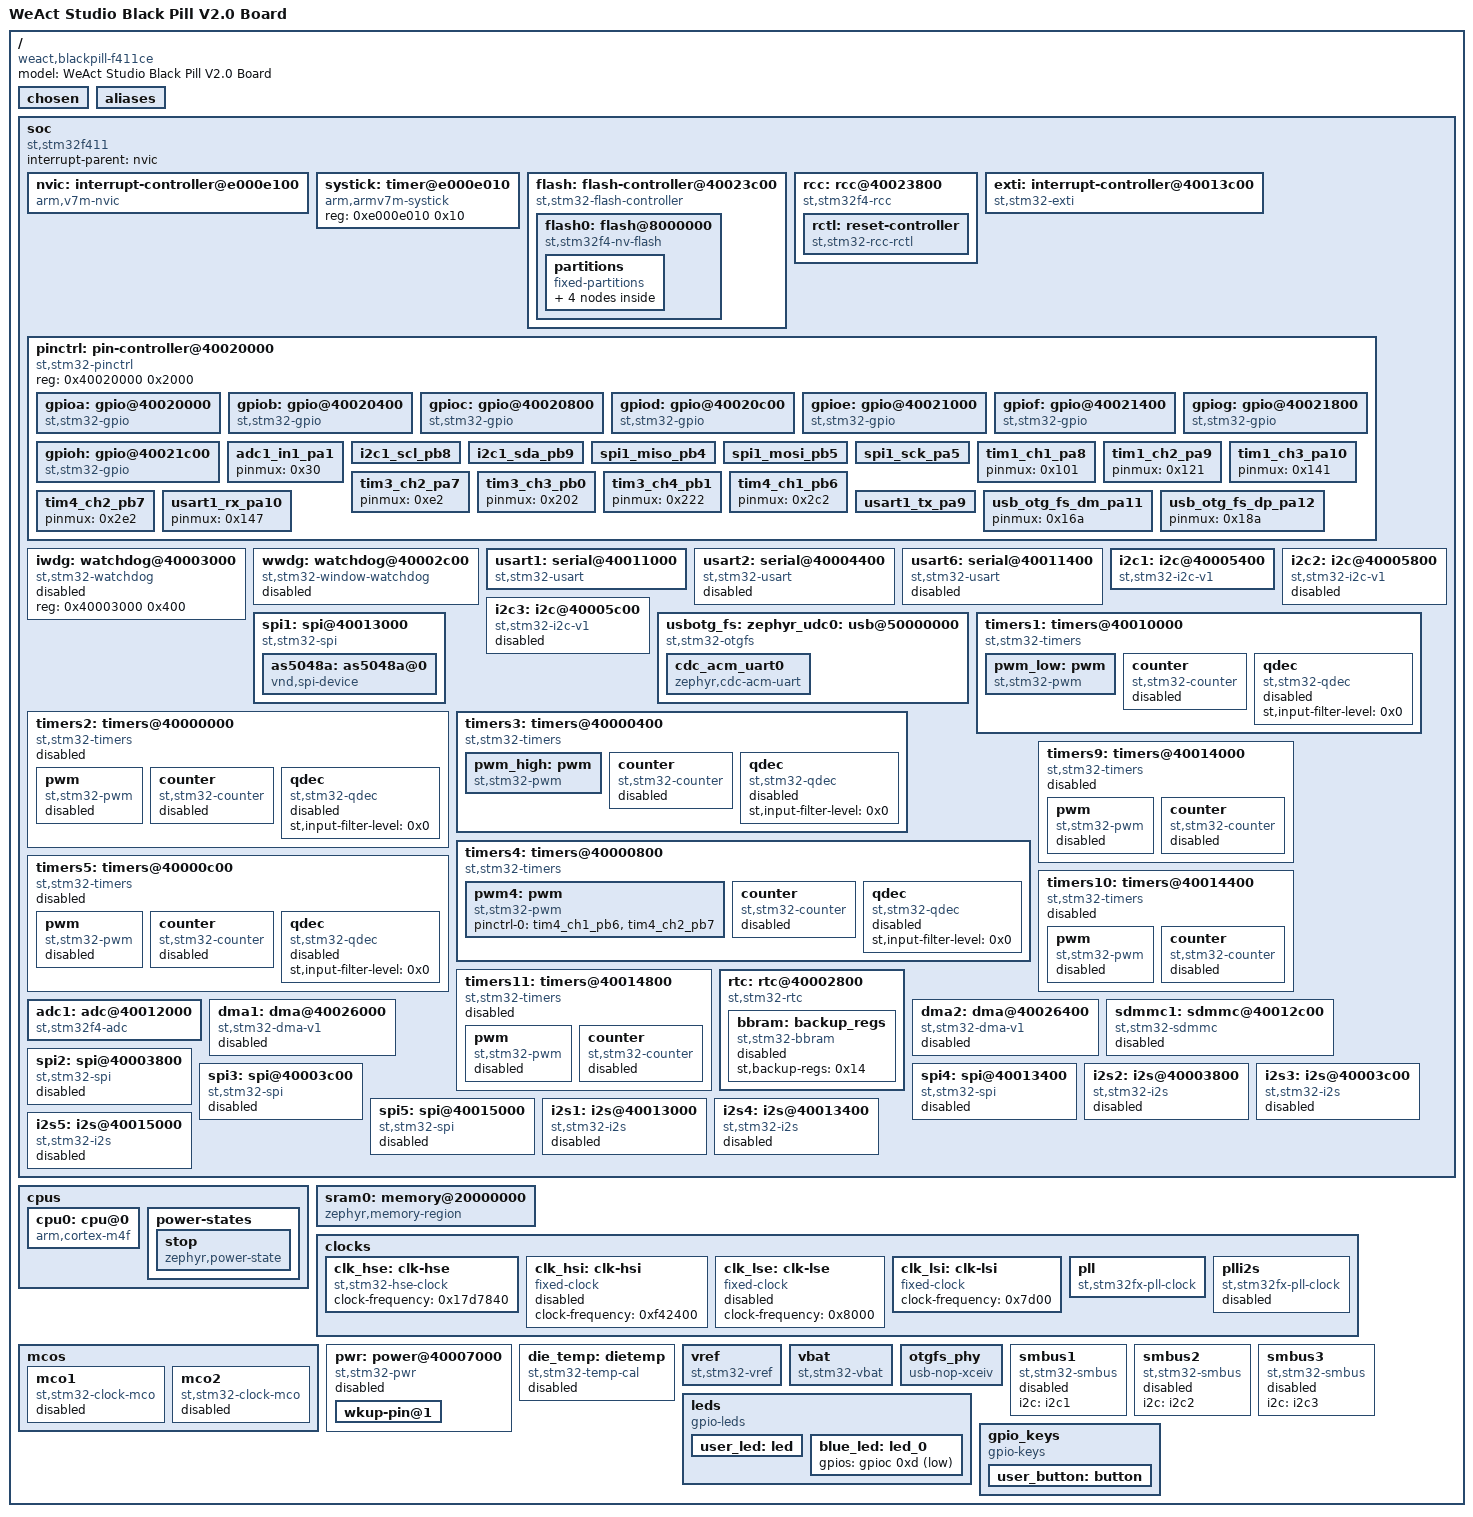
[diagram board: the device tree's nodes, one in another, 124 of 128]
/dts-v1/;

/* node '/' defined in zephyr/dts/common/skeleton.dtsi:9 */
/ {
	#address-cells = < 0x1 >;                     /* in zephyr/dts/common/skeleton.dtsi:10 */
	#size-cells = < 0x1 >;                        /* in zephyr/dts/common/skeleton.dtsi:11 */
	model = "WeAct Studio Black Pill V2.0 Board"; /* in zephyr/boards/weact/blackpill_f411ce/blackpill_f411ce.dts:14 */
	compatible = "weact,blackpill-f411ce";        /* in zephyr/boards/weact/blackpill_f411ce/blackpill_f411ce.dts:15 */

	/* node '/chosen' defined in zephyr/dts/common/skeleton.dtsi:13 */
	chosen {
		zephyr,flash-controller = &flash;  /* in zephyr/dts/arm/st/f4/stm32f4.dtsi:26 */
		zephyr,cortex-m-idle-timer = &rtc; /* in zephyr/dts/arm/st/f4/stm32f4.dtsi:27 */
		zephyr,shell-uart = &usart1;       /* in zephyr/boards/weact/blackpill_f411ce/blackpill_f411ce.dts:19 */
		zephyr,sram = &sram0;              /* in zephyr/boards/weact/blackpill_f411ce/blackpill_f411ce.dts:20 */
		zephyr,flash = &flash0;            /* in zephyr/boards/weact/blackpill_f411ce/blackpill_f411ce.dts:21 */
		zephyr,console = &cdc_acm_uart0;   /* in haptic/app.overlay:4 */
	};

	/* node '/aliases' defined in zephyr/dts/common/skeleton.dtsi:15 */
	aliases {
		volt-sensor0 = &vref; /* in zephyr/boards/weact/blackpill_f411ce/blackpill_f411ce.dts:46 */
		volt-sensor1 = &vbat; /* in zephyr/boards/weact/blackpill_f411ce/blackpill_f411ce.dts:47 */
		led0 = &blue_led;     /* in haptic/app.overlay:16 */
		sw0 = &user_button;   /* in haptic/app.overlay:17 */
	};

	/* node '/soc' defined in zephyr/dts/arm/armv7-m.dtsi:6 */
	soc {
		#address-cells = < 0x1 >;     /* in zephyr/dts/arm/armv7-m.dtsi:7 */
		#size-cells = < 0x1 >;        /* in zephyr/dts/arm/armv7-m.dtsi:8 */
		interrupt-parent = < &nvic >; /* in zephyr/dts/arm/armv7-m.dtsi:10 */
		ranges;                       /* in zephyr/dts/arm/armv7-m.dtsi:11 */
		compatible = "st,stm32f411",
		             "st,stm32f4",
		             "simple-bus";    /* in zephyr/dts/arm/st/f4/stm32f411.dtsi:11 */

		/* node '/soc/interrupt-controller@e000e100' defined in zephyr/dts/arm/armv7-m.dtsi:13 */
		nvic: interrupt-controller@e000e100 {
			#address-cells = < 0x1 >;            /* in zephyr/dts/arm/armv7-m.dtsi:14 */
			compatible = "arm,v7m-nvic";         /* in zephyr/dts/arm/armv7-m.dtsi:15 */
			reg = < 0xe000e100 0xc00 >;          /* in zephyr/dts/arm/armv7-m.dtsi:16 */
			interrupt-controller;                /* in zephyr/dts/arm/armv7-m.dtsi:17 */
			#interrupt-cells = < 0x2 >;          /* in zephyr/dts/arm/armv7-m.dtsi:18 */
			arm,num-irq-priority-bits = < 0x4 >; /* in zephyr/dts/arm/st/f4/stm32f4.dtsi:678 */
			phandle = < 0x1 >;                   /* in zephyr/dts/arm/armv7-m.dtsi:10 */
		};

		/* node '/soc/timer@e000e010' defined in zephyr/dts/arm/armv7-m.dtsi:21 */
		systick: timer@e000e010 {
			compatible = "arm,armv7m-systick"; /* in zephyr/dts/arm/armv7-m.dtsi:22 */
			reg = < 0xe000e010 0x10 >;         /* in zephyr/dts/arm/armv7-m.dtsi:23 */
		};

		/* node '/soc/flash-controller@40023c00' defined in zephyr/dts/arm/st/f4/stm32f4.dtsi:110 */
		flash: flash-controller@40023c00 {
			compatible = "st,stm32-flash-controller",
			             "st,stm32f4-flash-controller"; /* in zephyr/dts/arm/st/f4/stm32f4.dtsi:111 */
			reg = < 0x40023c00 0x400 >;                 /* in zephyr/dts/arm/st/f4/stm32f4.dtsi:112 */
			interrupts = < 0x4 0x0 >;                   /* in zephyr/dts/arm/st/f4/stm32f4.dtsi:113 */
			#address-cells = < 0x1 >;                   /* in zephyr/dts/arm/st/f4/stm32f4.dtsi:115 */
			#size-cells = < 0x1 >;                      /* in zephyr/dts/arm/st/f4/stm32f4.dtsi:116 */

			/* node '/soc/flash-controller@40023c00/flash@8000000' defined in zephyr/dts/arm/st/f4/stm32f4.dtsi:118 */
			flash0: flash@8000000 {
				compatible = "st,stm32f4-nv-flash",
				             "st,stm32-nv-flash",
				             "soc-nv-flash";        /* in zephyr/dts/arm/st/f4/stm32f4.dtsi:119 */
				write-block-size = < 0x1 >;         /* in zephyr/dts/arm/st/f4/stm32f4.dtsi:122 */
				max-erase-time = < 0xfa0 >;         /* in zephyr/dts/arm/st/f4/stm32f4.dtsi:124 */
				reg = < 0x8000000 0x80000 >;        /* in zephyr/dts/arm/st/f4/stm32f411Xe.dtsi:17 */

				/* node '/soc/flash-controller@40023c00/flash@8000000/partitions' defined in zephyr/boards/weact/blackpill_f411ce/blackpill_f411ce.dts:52 */
				partitions {
					compatible = "fixed-partitions"; /* in zephyr/boards/weact/blackpill_f411ce/blackpill_f411ce.dts:53 */
					#address-cells = < 0x1 >;        /* in zephyr/boards/weact/blackpill_f411ce/blackpill_f411ce.dts:54 */
					#size-cells = < 0x1 >;           /* in zephyr/boards/weact/blackpill_f411ce/blackpill_f411ce.dts:55 */

					/* node '/soc/flash-controller@40023c00/flash@8000000/partitions/partition@0' defined in zephyr/boards/weact/blackpill_f411ce/blackpill_f411ce.dts:57 */
					boot_partition: partition@0 {
						label = "mcuboot";    /* in zephyr/boards/weact/blackpill_f411ce/blackpill_f411ce.dts:58 */
						reg = < 0x0 0x8000 >; /* in zephyr/boards/weact/blackpill_f411ce/blackpill_f411ce.dts:59 */
						read-only;            /* in zephyr/boards/weact/blackpill_f411ce/blackpill_f411ce.dts:60 */
					};

					/* node '/soc/flash-controller@40023c00/flash@8000000/partitions/partition@20000' defined in zephyr/boards/weact/blackpill_f411ce/blackpill_f411ce.dts:69 */
					slot0_partition: partition@20000 {
						label = "image-0";         /* in zephyr/boards/weact/blackpill_f411ce/blackpill_f411ce.dts:70 */
						reg = < 0x20000 0x20000 >; /* in zephyr/boards/weact/blackpill_f411ce/blackpill_f411ce.dts:71 */
					};

					/* node '/soc/flash-controller@40023c00/flash@8000000/partitions/partition@40000' defined in zephyr/boards/weact/blackpill_f411ce/blackpill_f411ce.dts:74 */
					slot1_partition: partition@40000 {
						label = "image-1";         /* in zephyr/boards/weact/blackpill_f411ce/blackpill_f411ce.dts:75 */
						reg = < 0x40000 0x20000 >; /* in zephyr/boards/weact/blackpill_f411ce/blackpill_f411ce.dts:76 */
					};

					/* node '/soc/flash-controller@40023c00/flash@8000000/partitions/partition@60000' defined in zephyr/boards/weact/blackpill_f411ce/blackpill_f411ce.dts:79 */
					scratch_partition: partition@60000 {
						label = "image-scratch";   /* in zephyr/boards/weact/blackpill_f411ce/blackpill_f411ce.dts:80 */
						reg = < 0x60000 0x20000 >; /* in zephyr/boards/weact/blackpill_f411ce/blackpill_f411ce.dts:81 */
					};
				};
			};
		};

		/* node '/soc/rcc@40023800' defined in zephyr/dts/arm/st/f4/stm32f4.dtsi:128 */
		rcc: rcc@40023800 {
			compatible = "st,stm32f4-rcc";   /* in zephyr/dts/arm/st/f4/stm32f4.dtsi:129 */
			#clock-cells = < 0x2 >;          /* in zephyr/dts/arm/st/f4/stm32f4.dtsi:130 */
			reg = < 0x40023800 0x400 >;      /* in zephyr/dts/arm/st/f4/stm32f4.dtsi:131 */
			clocks = < &pll >;               /* in zephyr/boards/weact/blackpill_f411ce/blackpill_f411ce.dts:156 */
			clock-frequency = < 0x5b8d800 >; /* in zephyr/boards/weact/blackpill_f411ce/blackpill_f411ce.dts:157 */
			ahb-prescaler = < 0x1 >;         /* in zephyr/boards/weact/blackpill_f411ce/blackpill_f411ce.dts:158 */
			apb1-prescaler = < 0x2 >;        /* in zephyr/boards/weact/blackpill_f411ce/blackpill_f411ce.dts:159 */
			apb2-prescaler = < 0x1 >;        /* in zephyr/boards/weact/blackpill_f411ce/blackpill_f411ce.dts:160 */
			phandle = < 0x3 >;               /* in zephyr/dts/arm/st/f4/stm32f4.dtsi:145 */

			/* node '/soc/rcc@40023800/reset-controller' defined in zephyr/dts/arm/st/f4/stm32f4.dtsi:133 */
			rctl: reset-controller {
				compatible = "st,stm32-rcc-rctl"; /* in zephyr/dts/arm/st/f4/stm32f4.dtsi:134 */
				#reset-cells = < 0x1 >;           /* in zephyr/dts/arm/st/f4/stm32f4.dtsi:135 */
				phandle = < 0x4 >;                /* in zephyr/dts/arm/st/f4/stm32f4.dtsi:244 */
			};
		};

		/* node '/soc/interrupt-controller@40013c00' defined in zephyr/dts/arm/st/f4/stm32f4.dtsi:139 */
		exti: interrupt-controller@40013c00 {
			compatible = "st,stm32-exti";  /* in zephyr/dts/arm/st/f4/stm32f4.dtsi:140 */
			interrupt-controller;          /* in zephyr/dts/arm/st/f4/stm32f4.dtsi:141 */
			#interrupt-cells = < 0x1 >;    /* in zephyr/dts/arm/st/f4/stm32f4.dtsi:142 */
			#address-cells = < 0x0 >;      /* in zephyr/dts/arm/st/f4/stm32f4.dtsi:143 */
			reg = < 0x40013c00 0x400 >;    /* in zephyr/dts/arm/st/f4/stm32f4.dtsi:144 */
			clocks = < &rcc 0x44 0x4000 >; /* in zephyr/dts/arm/st/f4/stm32f4.dtsi:145 */
			num-lines = < 0x20 >;          /* in zephyr/dts/arm/st/f4/stm32f4.dtsi:146 */
			interrupts = < 0x6 0x0 >,
			             < 0x7 0x0 >,
			             < 0x8 0x0 >,
			             < 0x9 0x0 >,
			             < 0xa 0x0 >,
			             < 0x17 0x0 >,
			             < 0x28 0x0 >;     /* in zephyr/dts/arm/st/f4/stm32f4.dtsi:147 */
			interrupt-names = "line0",
			                  "line1",
			                  "line2",
			                  "line3",
			                  "line4",
			                  "line5-9",
			                  "line10-15"; /* in zephyr/dts/arm/st/f4/stm32f4.dtsi:149 */
			line-ranges = < 0x0 0x1 >,
			              < 0x1 0x1 >,
			              < 0x2 0x1 >,
			              < 0x3 0x1 >,
			              < 0x4 0x1 >,
			              < 0x5 0x5 >,
			              < 0xa 0x6 >;     /* in zephyr/dts/arm/st/f4/stm32f4.dtsi:151 */
		};

		/* node '/soc/pin-controller@40020000' defined in zephyr/dts/arm/st/f4/stm32f4.dtsi:155 */
		pinctrl: pin-controller@40020000 {
			compatible = "st,stm32-pinctrl"; /* in zephyr/dts/arm/st/f4/stm32f4.dtsi:156 */
			#address-cells = < 0x1 >;        /* in zephyr/dts/arm/st/f4/stm32f4.dtsi:157 */
			#size-cells = < 0x1 >;           /* in zephyr/dts/arm/st/f4/stm32f4.dtsi:158 */
			reg = < 0x40020000 0x2000 >;     /* in zephyr/dts/arm/st/f4/stm32f4.dtsi:159 */

			/* node '/soc/pin-controller@40020000/gpio@40020000' defined in zephyr/dts/arm/st/f4/stm32f4.dtsi:161 */
			gpioa: gpio@40020000 {
				compatible = "st,stm32-gpio"; /* in zephyr/dts/arm/st/f4/stm32f4.dtsi:162 */
				gpio-controller;              /* in zephyr/dts/arm/st/f4/stm32f4.dtsi:163 */
				#gpio-cells = < 0x2 >;        /* in zephyr/dts/arm/st/f4/stm32f4.dtsi:164 */
				reg = < 0x40020000 0x400 >;   /* in zephyr/dts/arm/st/f4/stm32f4.dtsi:165 */
				clocks = < &rcc 0x30 0x1 >;   /* in zephyr/dts/arm/st/f4/stm32f4.dtsi:166 */
				phandle = < 0xc >;            /* in haptic/app.overlay:34 */
			};

			/* node '/soc/pin-controller@40020000/gpio@40020400' defined in zephyr/dts/arm/st/f4/stm32f4.dtsi:169 */
			gpiob: gpio@40020400 {
				compatible = "st,stm32-gpio"; /* in zephyr/dts/arm/st/f4/stm32f4.dtsi:170 */
				gpio-controller;              /* in zephyr/dts/arm/st/f4/stm32f4.dtsi:171 */
				#gpio-cells = < 0x2 >;        /* in zephyr/dts/arm/st/f4/stm32f4.dtsi:172 */
				reg = < 0x40020400 0x400 >;   /* in zephyr/dts/arm/st/f4/stm32f4.dtsi:173 */
				clocks = < &rcc 0x30 0x2 >;   /* in zephyr/dts/arm/st/f4/stm32f4.dtsi:174 */
			};

			/* node '/soc/pin-controller@40020000/gpio@40020800' defined in zephyr/dts/arm/st/f4/stm32f4.dtsi:177 */
			gpioc: gpio@40020800 {
				compatible = "st,stm32-gpio"; /* in zephyr/dts/arm/st/f4/stm32f4.dtsi:178 */
				gpio-controller;              /* in zephyr/dts/arm/st/f4/stm32f4.dtsi:179 */
				#gpio-cells = < 0x2 >;        /* in zephyr/dts/arm/st/f4/stm32f4.dtsi:180 */
				reg = < 0x40020800 0x400 >;   /* in zephyr/dts/arm/st/f4/stm32f4.dtsi:181 */
				clocks = < &rcc 0x30 0x4 >;   /* in zephyr/dts/arm/st/f4/stm32f4.dtsi:182 */
				phandle = < 0x21 >;           /* in zephyr/boards/weact/blackpill_f411ce/blackpill_f411ce.dts:28 */
			};

			/* node '/soc/pin-controller@40020000/gpio@40020c00' defined in zephyr/dts/arm/st/f4/stm32f4.dtsi:185 */
			gpiod: gpio@40020c00 {
				compatible = "st,stm32-gpio"; /* in zephyr/dts/arm/st/f4/stm32f4.dtsi:186 */
				gpio-controller;              /* in zephyr/dts/arm/st/f4/stm32f4.dtsi:187 */
				#gpio-cells = < 0x2 >;        /* in zephyr/dts/arm/st/f4/stm32f4.dtsi:188 */
				reg = < 0x40020c00 0x400 >;   /* in zephyr/dts/arm/st/f4/stm32f4.dtsi:189 */
				clocks = < &rcc 0x30 0x8 >;   /* in zephyr/dts/arm/st/f4/stm32f4.dtsi:190 */
			};

			/* node '/soc/pin-controller@40020000/gpio@40021000' defined in zephyr/dts/arm/st/f4/stm32f4.dtsi:193 */
			gpioe: gpio@40021000 {
				compatible = "st,stm32-gpio"; /* in zephyr/dts/arm/st/f4/stm32f4.dtsi:194 */
				gpio-controller;              /* in zephyr/dts/arm/st/f4/stm32f4.dtsi:195 */
				#gpio-cells = < 0x2 >;        /* in zephyr/dts/arm/st/f4/stm32f4.dtsi:196 */
				reg = < 0x40021000 0x400 >;   /* in zephyr/dts/arm/st/f4/stm32f4.dtsi:197 */
				clocks = < &rcc 0x30 0x10 >;  /* in zephyr/dts/arm/st/f4/stm32f4.dtsi:198 */
			};

			/* node '/soc/pin-controller@40020000/gpio@40021400' defined in zephyr/dts/arm/st/f4/stm32f4.dtsi:201 */
			gpiof: gpio@40021400 {
				compatible = "st,stm32-gpio"; /* in zephyr/dts/arm/st/f4/stm32f4.dtsi:202 */
				gpio-controller;              /* in zephyr/dts/arm/st/f4/stm32f4.dtsi:203 */
				#gpio-cells = < 0x2 >;        /* in zephyr/dts/arm/st/f4/stm32f4.dtsi:204 */
				reg = < 0x40021400 0x400 >;   /* in zephyr/dts/arm/st/f4/stm32f4.dtsi:205 */
				clocks = < &rcc 0x30 0x20 >;  /* in zephyr/dts/arm/st/f4/stm32f4.dtsi:206 */
			};

			/* node '/soc/pin-controller@40020000/gpio@40021800' defined in zephyr/dts/arm/st/f4/stm32f4.dtsi:209 */
			gpiog: gpio@40021800 {
				compatible = "st,stm32-gpio"; /* in zephyr/dts/arm/st/f4/stm32f4.dtsi:210 */
				gpio-controller;              /* in zephyr/dts/arm/st/f4/stm32f4.dtsi:211 */
				#gpio-cells = < 0x2 >;        /* in zephyr/dts/arm/st/f4/stm32f4.dtsi:212 */
				reg = < 0x40021800 0x400 >;   /* in zephyr/dts/arm/st/f4/stm32f4.dtsi:213 */
				clocks = < &rcc 0x30 0x40 >;  /* in zephyr/dts/arm/st/f4/stm32f4.dtsi:214 */
			};

			/* node '/soc/pin-controller@40020000/gpio@40021c00' defined in zephyr/dts/arm/st/f4/stm32f4.dtsi:217 */
			gpioh: gpio@40021c00 {
				compatible = "st,stm32-gpio"; /* in zephyr/dts/arm/st/f4/stm32f4.dtsi:218 */
				gpio-controller;              /* in zephyr/dts/arm/st/f4/stm32f4.dtsi:219 */
				#gpio-cells = < 0x2 >;        /* in zephyr/dts/arm/st/f4/stm32f4.dtsi:220 */
				reg = < 0x40021c00 0x400 >;   /* in zephyr/dts/arm/st/f4/stm32f4.dtsi:221 */
				clocks = < &rcc 0x30 0x80 >;  /* in zephyr/dts/arm/st/f4/stm32f4.dtsi:222 */
			};

			/* node '/soc/pin-controller@40020000/adc1_in1_pa1' defined in modules/hal/stm32/dts/st/f4/stm32f411c(c-e)ux-pinctrl.dtsi:19 */
			adc1_in1_pa1: adc1_in1_pa1 {
				pinmux = < 0x30 >;  /* in modules/hal/stm32/dts/st/f4/stm32f411c(c-e)ux-pinctrl.dtsi:20 */
				phandle = < 0x18 >; /* in zephyr/boards/weact/blackpill_f411ce/blackpill_f411ce.dts:130 */
			};

			/* node '/soc/pin-controller@40020000/i2c1_scl_pb8' defined in modules/hal/stm32/dts/st/f4/stm32f411c(c-e)ux-pinctrl.dtsi:209 */
			i2c1_scl_pb8: i2c1_scl_pb8 {
				pinmux = < 0x304 >; /* in modules/hal/stm32/dts/st/f4/stm32f411c(c-e)ux-pinctrl.dtsi:210 */
				bias-pull-up;       /* in modules/hal/stm32/dts/st/f4/stm32f411c(c-e)ux-pinctrl.dtsi:211 */
				drive-open-drain;   /* in modules/hal/stm32/dts/st/f4/stm32f411c(c-e)ux-pinctrl.dtsi:212 */
				phandle = < 0x7 >;  /* in zephyr/boards/weact/blackpill_f411ce/blackpill_f411ce.dts:104 */
			};

			/* node '/soc/pin-controller@40020000/i2c1_sda_pb9' defined in modules/hal/stm32/dts/st/f4/stm32f411c(c-e)ux-pinctrl.dtsi:235 */
			i2c1_sda_pb9: i2c1_sda_pb9 {
				pinmux = < 0x324 >; /* in modules/hal/stm32/dts/st/f4/stm32f411c(c-e)ux-pinctrl.dtsi:236 */
				bias-pull-up;       /* in modules/hal/stm32/dts/st/f4/stm32f411c(c-e)ux-pinctrl.dtsi:237 */
				drive-open-drain;   /* in modules/hal/stm32/dts/st/f4/stm32f411c(c-e)ux-pinctrl.dtsi:238 */
				phandle = < 0x8 >;  /* in zephyr/boards/weact/blackpill_f411ce/blackpill_f411ce.dts:104 */
			};

			/* node '/soc/pin-controller@40020000/spi1_miso_pb4' defined in modules/hal/stm32/dts/st/f4/stm32f411c(c-e)ux-pinctrl.dtsi:510 */
			spi1_miso_pb4: spi1_miso_pb4 {
				pinmux = < 0x285 >;            /* in modules/hal/stm32/dts/st/f4/stm32f411c(c-e)ux-pinctrl.dtsi:511 */
				bias-pull-down;                /* in modules/hal/stm32/dts/st/f4/stm32f411c(c-e)ux-pinctrl.dtsi:512 */
				slew-rate = "very-high-speed"; /* in modules/hal/stm32/dts/st/f4/stm32f411c(c-e)ux-pinctrl.dtsi:513 */
				phandle = < 0xa >;             /* in haptic/app.overlay:32 */
			};

			/* node '/soc/pin-controller@40020000/spi1_mosi_pb5' defined in modules/hal/stm32/dts/st/f4/stm32f411c(c-e)ux-pinctrl.dtsi:548 */
			spi1_mosi_pb5: spi1_mosi_pb5 {
				pinmux = < 0x2a5 >;            /* in modules/hal/stm32/dts/st/f4/stm32f411c(c-e)ux-pinctrl.dtsi:549 */
				bias-pull-down;                /* in modules/hal/stm32/dts/st/f4/stm32f411c(c-e)ux-pinctrl.dtsi:550 */
				slew-rate = "very-high-speed"; /* in modules/hal/stm32/dts/st/f4/stm32f411c(c-e)ux-pinctrl.dtsi:551 */
				phandle = < 0xb >;             /* in haptic/app.overlay:32 */
			};

			/* node '/soc/pin-controller@40020000/spi1_sck_pa5' defined in modules/hal/stm32/dts/st/f4/stm32f411c(c-e)ux-pinctrl.dtsi:636 */
			spi1_sck_pa5: spi1_sck_pa5 {
				pinmux = < 0xa5 >;             /* in modules/hal/stm32/dts/st/f4/stm32f411c(c-e)ux-pinctrl.dtsi:637 */
				bias-pull-down;                /* in modules/hal/stm32/dts/st/f4/stm32f411c(c-e)ux-pinctrl.dtsi:638 */
				slew-rate = "very-high-speed"; /* in modules/hal/stm32/dts/st/f4/stm32f411c(c-e)ux-pinctrl.dtsi:639 */
				phandle = < 0x9 >;             /* in haptic/app.overlay:32 */
			};

			/* node '/soc/pin-controller@40020000/tim1_ch1_pa8' defined in modules/hal/stm32/dts/st/f4/stm32f411c(c-e)ux-pinctrl.dtsi:704 */
			tim1_ch1_pa8: tim1_ch1_pa8 {
				pinmux = < 0x101 >; /* in modules/hal/stm32/dts/st/f4/stm32f411c(c-e)ux-pinctrl.dtsi:705 */
				phandle = < 0x10 >; /* in haptic/app.overlay:52 */
			};

			/* node '/soc/pin-controller@40020000/tim1_ch2_pa9' defined in modules/hal/stm32/dts/st/f4/stm32f411c(c-e)ux-pinctrl.dtsi:708 */
			tim1_ch2_pa9: tim1_ch2_pa9 {
				pinmux = < 0x121 >; /* in modules/hal/stm32/dts/st/f4/stm32f411c(c-e)ux-pinctrl.dtsi:709 */
				phandle = < 0x11 >; /* in haptic/app.overlay:52 */
			};

			/* node '/soc/pin-controller@40020000/tim1_ch3_pa10' defined in modules/hal/stm32/dts/st/f4/stm32f411c(c-e)ux-pinctrl.dtsi:712 */
			tim1_ch3_pa10: tim1_ch3_pa10 {
				pinmux = < 0x141 >; /* in modules/hal/stm32/dts/st/f4/stm32f411c(c-e)ux-pinctrl.dtsi:713 */
				phandle = < 0x12 >; /* in haptic/app.overlay:52 */
			};

			/* node '/soc/pin-controller@40020000/tim3_ch2_pa7' defined in modules/hal/stm32/dts/st/f4/stm32f411c(c-e)ux-pinctrl.dtsi:780 */
			tim3_ch2_pa7: tim3_ch2_pa7 {
				pinmux = < 0xe2 >;  /* in modules/hal/stm32/dts/st/f4/stm32f411c(c-e)ux-pinctrl.dtsi:781 */
				phandle = < 0x13 >; /* in haptic/app.overlay:62 */
			};

			/* node '/soc/pin-controller@40020000/tim3_ch3_pb0' defined in modules/hal/stm32/dts/st/f4/stm32f411c(c-e)ux-pinctrl.dtsi:784 */
			tim3_ch3_pb0: tim3_ch3_pb0 {
				pinmux = < 0x202 >; /* in modules/hal/stm32/dts/st/f4/stm32f411c(c-e)ux-pinctrl.dtsi:785 */
				phandle = < 0x14 >; /* in haptic/app.overlay:62 */
			};

			/* node '/soc/pin-controller@40020000/tim3_ch4_pb1' defined in modules/hal/stm32/dts/st/f4/stm32f411c(c-e)ux-pinctrl.dtsi:788 */
			tim3_ch4_pb1: tim3_ch4_pb1 {
				pinmux = < 0x222 >; /* in modules/hal/stm32/dts/st/f4/stm32f411c(c-e)ux-pinctrl.dtsi:789 */
				phandle = < 0x15 >; /* in haptic/app.overlay:62 */
			};

			/* node '/soc/pin-controller@40020000/tim4_ch1_pb6' defined in modules/hal/stm32/dts/st/f4/stm32f411c(c-e)ux-pinctrl.dtsi:800 */
			tim4_ch1_pb6: tim4_ch1_pb6 {
				pinmux = < 0x2c2 >; /* in modules/hal/stm32/dts/st/f4/stm32f411c(c-e)ux-pinctrl.dtsi:801 */
				phandle = < 0x16 >; /* in zephyr/boards/weact/blackpill_f411ce/blackpill_f411ce.dts:91 */
			};

			/* node '/soc/pin-controller@40020000/tim4_ch2_pb7' defined in modules/hal/stm32/dts/st/f4/stm32f411c(c-e)ux-pinctrl.dtsi:804 */
			tim4_ch2_pb7: tim4_ch2_pb7 {
				pinmux = < 0x2e2 >; /* in modules/hal/stm32/dts/st/f4/stm32f411c(c-e)ux-pinctrl.dtsi:805 */
				phandle = < 0x17 >; /* in zephyr/boards/weact/blackpill_f411ce/blackpill_f411ce.dts:91 */
			};

			/* node '/soc/pin-controller@40020000/usart1_rx_pa10' defined in modules/hal/stm32/dts/st/f4/stm32f411c(c-e)ux-pinctrl.dtsi:866 */
			usart1_rx_pa10: usart1_rx_pa10 {
				pinmux = < 0x147 >; /* in modules/hal/stm32/dts/st/f4/stm32f411c(c-e)ux-pinctrl.dtsi:867 */
				phandle = < 0x6 >;  /* in zephyr/boards/weact/blackpill_f411ce/blackpill_f411ce.dts:97 */
			};

			/* node '/soc/pin-controller@40020000/usart1_tx_pa9' defined in modules/hal/stm32/dts/st/f4/stm32f411c(c-e)ux-pinctrl.dtsi:888 */
			usart1_tx_pa9: usart1_tx_pa9 {
				pinmux = < 0x127 >; /* in modules/hal/stm32/dts/st/f4/stm32f411c(c-e)ux-pinctrl.dtsi:889 */
				bias-pull-up;       /* in modules/hal/stm32/dts/st/f4/stm32f411c(c-e)ux-pinctrl.dtsi:890 */
				phandle = < 0x5 >;  /* in zephyr/boards/weact/blackpill_f411ce/blackpill_f411ce.dts:97 */
			};

			/* node '/soc/pin-controller@40020000/usb_otg_fs_dm_pa11' defined in modules/hal/stm32/dts/st/f4/stm32f411c(c-e)ux-pinctrl.dtsi:927 */
			usb_otg_fs_dm_pa11: usb_otg_fs_dm_pa11 {
				pinmux = < 0x16a >; /* in modules/hal/stm32/dts/st/f4/stm32f411c(c-e)ux-pinctrl.dtsi:928 */
				phandle = < 0xe >;  /* in zephyr/boards/weact/blackpill_f411ce/blackpill_f411ce.dts:124 */
			};

			/* node '/soc/pin-controller@40020000/usb_otg_fs_dp_pa12' defined in modules/hal/stm32/dts/st/f4/stm32f411c(c-e)ux-pinctrl.dtsi:931 */
			usb_otg_fs_dp_pa12: usb_otg_fs_dp_pa12 {
				pinmux = < 0x18a >; /* in modules/hal/stm32/dts/st/f4/stm32f411c(c-e)ux-pinctrl.dtsi:932 */
				phandle = < 0xf >;  /* in zephyr/boards/weact/blackpill_f411ce/blackpill_f411ce.dts:124 */
			};
		};

		/* node '/soc/watchdog@40003000' defined in zephyr/dts/arm/st/f4/stm32f4.dtsi:226 */
		iwdg: watchdog@40003000 {
			compatible = "st,stm32-watchdog"; /* in zephyr/dts/arm/st/f4/stm32f4.dtsi:227 */
			reg = < 0x40003000 0x400 >;       /* in zephyr/dts/arm/st/f4/stm32f4.dtsi:228 */
			status = "disabled";              /* in zephyr/dts/arm/st/f4/stm32f4.dtsi:229 */
		};

		/* node '/soc/watchdog@40002c00' defined in zephyr/dts/arm/st/f4/stm32f4.dtsi:232 */
		wwdg: watchdog@40002c00 {
			compatible = "st,stm32-window-watchdog"; /* in zephyr/dts/arm/st/f4/stm32f4.dtsi:233 */
			reg = < 0x40002c00 0x400 >;              /* in zephyr/dts/arm/st/f4/stm32f4.dtsi:234 */
			clocks = < &rcc 0x40 0x800 >;            /* in zephyr/dts/arm/st/f4/stm32f4.dtsi:235 */
			interrupts = < 0x0 0x7 >;                /* in zephyr/dts/arm/st/f4/stm32f4.dtsi:236 */
			status = "disabled";                     /* in zephyr/dts/arm/st/f4/stm32f4.dtsi:237 */
		};

		/* node '/soc/serial@40011000' defined in zephyr/dts/arm/st/f4/stm32f4.dtsi:240 */
		usart1: serial@40011000 {
			compatible = "st,stm32-usart",
			             "st,stm32-uart";                   /* in zephyr/dts/arm/st/f4/stm32f4.dtsi:241 */
			reg = < 0x40011000 0x400 >;                     /* in zephyr/dts/arm/st/f4/stm32f4.dtsi:242 */
			clocks = < &rcc 0x44 0x10 >;                    /* in zephyr/dts/arm/st/f4/stm32f4.dtsi:243 */
			resets = < &rctl 0x484 >;                       /* in zephyr/dts/arm/st/f4/stm32f4.dtsi:244 */
			interrupts = < 0x25 0x0 >;                      /* in zephyr/dts/arm/st/f4/stm32f4.dtsi:245 */
			pinctrl-0 = < &usart1_tx_pa9 &usart1_rx_pa10 >; /* in zephyr/boards/weact/blackpill_f411ce/blackpill_f411ce.dts:97 */
			pinctrl-names = "default";                      /* in zephyr/boards/weact/blackpill_f411ce/blackpill_f411ce.dts:98 */
			status = "okay";                                /* in zephyr/boards/weact/blackpill_f411ce/blackpill_f411ce.dts:99 */
			current-speed = < 0x1c200 >;                    /* in zephyr/boards/weact/blackpill_f411ce/blackpill_f411ce.dts:100 */
		};

		/* node '/soc/serial@40004400' defined in zephyr/dts/arm/st/f4/stm32f4.dtsi:249 */
		usart2: serial@40004400 {
			compatible = "st,stm32-usart",
			             "st,stm32-uart";   /* in zephyr/dts/arm/st/f4/stm32f4.dtsi:250 */
			reg = < 0x40004400 0x400 >;     /* in zephyr/dts/arm/st/f4/stm32f4.dtsi:251 */
			clocks = < &rcc 0x40 0x20000 >; /* in zephyr/dts/arm/st/f4/stm32f4.dtsi:252 */
			resets = < &rctl 0x411 >;       /* in zephyr/dts/arm/st/f4/stm32f4.dtsi:253 */
			interrupts = < 0x26 0x0 >;      /* in zephyr/dts/arm/st/f4/stm32f4.dtsi:254 */
			status = "disabled";            /* in zephyr/dts/arm/st/f4/stm32f4.dtsi:255 */
		};

		/* node '/soc/serial@40011400' defined in zephyr/dts/arm/st/f4/stm32f4.dtsi:258 */
		usart6: serial@40011400 {
			compatible = "st,stm32-usart",
			             "st,stm32-uart";  /* in zephyr/dts/arm/st/f4/stm32f4.dtsi:259 */
			reg = < 0x40011400 0x400 >;    /* in zephyr/dts/arm/st/f4/stm32f4.dtsi:260 */
			clocks = < &rcc 0x44 0x20 >;   /* in zephyr/dts/arm/st/f4/stm32f4.dtsi:261 */
			resets = < &rctl 0x485 >;      /* in zephyr/dts/arm/st/f4/stm32f4.dtsi:262 */
			interrupts = < 0x47 0x0 >;     /* in zephyr/dts/arm/st/f4/stm32f4.dtsi:263 */
			status = "disabled";           /* in zephyr/dts/arm/st/f4/stm32f4.dtsi:264 */
		};

		/* node '/soc/i2c@40005400' defined in zephyr/dts/arm/st/f4/stm32f4.dtsi:267 */
		i2c1: i2c@40005400 {
			compatible = "st,stm32-i2c-v1";              /* in zephyr/dts/arm/st/f4/stm32f4.dtsi:268 */
			#address-cells = < 0x1 >;                    /* in zephyr/dts/arm/st/f4/stm32f4.dtsi:270 */
			#size-cells = < 0x0 >;                       /* in zephyr/dts/arm/st/f4/stm32f4.dtsi:271 */
			reg = < 0x40005400 0x400 >;                  /* in zephyr/dts/arm/st/f4/stm32f4.dtsi:272 */
			clocks = < &rcc 0x40 0x200000 >;             /* in zephyr/dts/arm/st/f4/stm32f4.dtsi:273 */
			interrupts = < 0x1f 0x0 >,
			             < 0x20 0x0 >;                   /* in zephyr/dts/arm/st/f4/stm32f4.dtsi:274 */
			interrupt-names = "event",
			                  "error";                   /* in zephyr/dts/arm/st/f4/stm32f4.dtsi:275 */
			pinctrl-0 = < &i2c1_scl_pb8 &i2c1_sda_pb9 >; /* in zephyr/boards/weact/blackpill_f411ce/blackpill_f411ce.dts:104 */
			pinctrl-names = "default";                   /* in zephyr/boards/weact/blackpill_f411ce/blackpill_f411ce.dts:105 */
			status = "okay";                             /* in zephyr/boards/weact/blackpill_f411ce/blackpill_f411ce.dts:106 */
			clock-frequency = < 0x61a80 >;               /* in zephyr/boards/weact/blackpill_f411ce/blackpill_f411ce.dts:107 */
			phandle = < 0x1e >;                          /* in zephyr/dts/arm/st/f4/stm32f4.dtsi:656 */
		};

		/* node '/soc/i2c@40005800' defined in zephyr/dts/arm/st/f4/stm32f4.dtsi:279 */
		i2c2: i2c@40005800 {
			compatible = "st,stm32-i2c-v1";  /* in zephyr/dts/arm/st/f4/stm32f4.dtsi:280 */
			clock-frequency = < 0x186a0 >;   /* in zephyr/dts/arm/st/f4/stm32f4.dtsi:281 */
			#address-cells = < 0x1 >;        /* in zephyr/dts/arm/st/f4/stm32f4.dtsi:282 */
			#size-cells = < 0x0 >;           /* in zephyr/dts/arm/st/f4/stm32f4.dtsi:283 */
			reg = < 0x40005800 0x400 >;      /* in zephyr/dts/arm/st/f4/stm32f4.dtsi:284 */
			clocks = < &rcc 0x40 0x400000 >; /* in zephyr/dts/arm/st/f4/stm32f4.dtsi:285 */
			interrupts = < 0x21 0x0 >,
			             < 0x22 0x0 >;       /* in zephyr/dts/arm/st/f4/stm32f4.dtsi:286 */
			interrupt-names = "event",
			                  "error";       /* in zephyr/dts/arm/st/f4/stm32f4.dtsi:287 */
			status = "disabled";             /* in zephyr/dts/arm/st/f4/stm32f4.dtsi:288 */
			phandle = < 0x1f >;              /* in zephyr/dts/arm/st/f4/stm32f4.dtsi:664 */
		};

		/* node '/soc/i2c@40005c00' defined in zephyr/dts/arm/st/f4/stm32f4.dtsi:291 */
		i2c3: i2c@40005c00 {
			compatible = "st,stm32-i2c-v1";  /* in zephyr/dts/arm/st/f4/stm32f4.dtsi:292 */
			clock-frequency = < 0x186a0 >;   /* in zephyr/dts/arm/st/f4/stm32f4.dtsi:293 */
			#address-cells = < 0x1 >;        /* in zephyr/dts/arm/st/f4/stm32f4.dtsi:294 */
			#size-cells = < 0x0 >;           /* in zephyr/dts/arm/st/f4/stm32f4.dtsi:295 */
			reg = < 0x40005c00 0x400 >;      /* in zephyr/dts/arm/st/f4/stm32f4.dtsi:296 */
			clocks = < &rcc 0x40 0x800000 >; /* in zephyr/dts/arm/st/f4/stm32f4.dtsi:297 */
			interrupts = < 0x48 0x0 >,
			             < 0x49 0x0 >;       /* in zephyr/dts/arm/st/f4/stm32f4.dtsi:298 */
			interrupt-names = "event",
			                  "error";       /* in zephyr/dts/arm/st/f4/stm32f4.dtsi:299 */
			status = "disabled";             /* in zephyr/dts/arm/st/f4/stm32f4.dtsi:300 */
			phandle = < 0x20 >;              /* in zephyr/dts/arm/st/f4/stm32f4.dtsi:672 */
		};

		/* node '/soc/spi@40013000' defined in zephyr/dts/arm/st/f4/stm32f4.dtsi:303 */
		spi1: spi@40013000 {
			compatible = "st,stm32-spi";                                 /* in zephyr/dts/arm/st/f4/stm32f4.dtsi:304 */
			#address-cells = < 0x1 >;                                    /* in zephyr/dts/arm/st/f4/stm32f4.dtsi:305 */
			#size-cells = < 0x0 >;                                       /* in zephyr/dts/arm/st/f4/stm32f4.dtsi:306 */
			reg = < 0x40013000 0x400 >;                                  /* in zephyr/dts/arm/st/f4/stm32f4.dtsi:307 */
			clocks = < &rcc 0x44 0x1000 >;                               /* in zephyr/dts/arm/st/f4/stm32f4.dtsi:308 */
			interrupts = < 0x23 0x5 >;                                   /* in zephyr/dts/arm/st/f4/stm32f4.dtsi:309 */
			st,spi-data-width = "limited-8-16-bit";                      /* in zephyr/dts/arm/st/f4/stm32f4.dtsi:310 */
			status = "okay";                                             /* in haptic/app.overlay:31 */
			pinctrl-0 = < &spi1_sck_pa5 &spi1_miso_pb4 &spi1_mosi_pb5 >; /* in haptic/app.overlay:32 */
			pinctrl-names = "default";                                   /* in haptic/app.overlay:33 */
			cs-gpios = < &gpioa 0x4 0x1 >;                               /* in haptic/app.overlay:34 */

			/* node '/soc/spi@40013000/as5048a@0' defined in haptic/app.overlay:36 */
			as5048a: as5048a@0 {
				compatible = "vnd,spi-device";   /* in haptic/app.overlay:37 */
				reg = < 0x0 >;                   /* in haptic/app.overlay:38 */
				spi-max-frequency = < 0xf4240 >; /* in haptic/app.overlay:39 */
			};
		};

		/* node '/soc/usb@50000000' defined in zephyr/dts/arm/st/f4/stm32f4.dtsi:314 */
		usbotg_fs: zephyr_udc0: usb@50000000 {
			compatible = "st,stm32-otgfs";                           /* in zephyr/dts/arm/st/f4/stm32f4.dtsi:315 */
			reg = < 0x50000000 0x40000 >;                            /* in zephyr/dts/arm/st/f4/stm32f4.dtsi:316 */
			interrupts = < 0x43 0x0 >;                               /* in zephyr/dts/arm/st/f4/stm32f4.dtsi:317 */
			interrupt-names = "otgfs";                               /* in zephyr/dts/arm/st/f4/stm32f4.dtsi:318 */
			num-bidir-endpoints = < 0x4 >;                           /* in zephyr/dts/arm/st/f4/stm32f4.dtsi:319 */
			ram-size = < 0x500 >;                                    /* in zephyr/dts/arm/st/f4/stm32f4.dtsi:320 */
			maximum-speed = "full-speed";                            /* in zephyr/dts/arm/st/f4/stm32f4.dtsi:321 */
			phys = < &otgfs_phy >;                                   /* in zephyr/dts/arm/st/f4/stm32f4.dtsi:322 */
			clocks = < &rcc 0x34 0x80 >,
			         < &rcc 0x7 0xff >;                              /* in zephyr/dts/arm/st/f4/stm32f4.dtsi:323 */
			pinctrl-0 = < &usb_otg_fs_dm_pa11 &usb_otg_fs_dp_pa12 >; /* in zephyr/boards/weact/blackpill_f411ce/blackpill_f411ce.dts:124 */
			pinctrl-names = "default";                               /* in zephyr/boards/weact/blackpill_f411ce/blackpill_f411ce.dts:125 */
			status = "okay";                                         /* in haptic/app.overlay:23 */

			/* node '/soc/usb@50000000/cdc_acm_uart0' defined in haptic/app.overlay:24 */
			cdc_acm_uart0: cdc_acm_uart0 {
				compatible = "zephyr,cdc-acm-uart"; /* in haptic/app.overlay:25 */
			};
		};

		/* node '/soc/timers@40010000' defined in zephyr/dts/arm/st/f4/stm32f4.dtsi:328 */
		timers1: timers@40010000 {
			compatible = "st,stm32-timers"; /* in zephyr/dts/arm/st/f4/stm32f4.dtsi:329 */
			reg = < 0x40010000 0x400 >;     /* in zephyr/dts/arm/st/f4/stm32f4.dtsi:330 */
			clocks = < &rcc 0x44 0x1 >,
			         < &rcc 0x16 0xff >;    /* in zephyr/dts/arm/st/f4/stm32f4.dtsi:331 */
			resets = < &rctl 0x480 >;       /* in zephyr/dts/arm/st/f4/stm32f4.dtsi:333 */
			interrupts = < 0x18 0x0 >,
			             < 0x19 0x0 >,
			             < 0x1a 0x0 >,
			             < 0x1b 0x0 >;      /* in zephyr/dts/arm/st/f4/stm32f4.dtsi:334 */
			interrupt-names = "brk",
			                  "up",
			                  "trgcom",
			                  "cc";         /* in zephyr/dts/arm/st/f4/stm32f4.dtsi:335 */
			st,prescaler = < 0x0 >;         /* in zephyr/dts/arm/st/f4/stm32f4.dtsi:336 */
			status = "okay";                /* in haptic/app.overlay:49 */

			/* node '/soc/timers@40010000/pwm' defined in zephyr/dts/arm/st/f4/stm32f4.dtsi:339 */
			pwm_low: pwm {
				compatible = "st,stm32-pwm";                                /* in zephyr/dts/arm/st/f4/stm32f4.dtsi:340 */
				#pwm-cells = < 0x3 >;                                       /* in zephyr/dts/arm/st/f4/stm32f4.dtsi:342 */
				status = "okay";                                            /* in haptic/app.overlay:51 */
				pinctrl-0 = < &tim1_ch1_pa8 &tim1_ch2_pa9 &tim1_ch3_pa10 >; /* in haptic/app.overlay:52 */
				pinctrl-names = "default";                                  /* in haptic/app.overlay:53 */
			};

			/* node '/soc/timers@40010000/counter' defined in zephyr/dts/arm/st/f4/stm32f4.dtsi:345 */
			counter {
				compatible = "st,stm32-counter"; /* in zephyr/dts/arm/st/f4/stm32f4.dtsi:346 */
				status = "disabled";             /* in zephyr/dts/arm/st/f4/stm32f4.dtsi:347 */
			};

			/* node '/soc/timers@40010000/qdec' defined in zephyr/dts/arm/st/f4/stm32f4.dtsi:350 */
			qdec {
				compatible = "st,stm32-qdec";    /* in zephyr/dts/arm/st/f4/stm32f4.dtsi:351 */
				st,input-filter-level = < 0x0 >; /* in zephyr/dts/arm/st/f4/stm32f4.dtsi:352 */
				status = "disabled";             /* in zephyr/dts/arm/st/f4/stm32f4.dtsi:353 */
			};
		};

		/* node '/soc/timers@40000000' defined in zephyr/dts/arm/st/f4/stm32f4.dtsi:357 */
		timers2: timers@40000000 {
			compatible = "st,stm32-timers"; /* in zephyr/dts/arm/st/f4/stm32f4.dtsi:358 */
			reg = < 0x40000000 0x400 >;     /* in zephyr/dts/arm/st/f4/stm32f4.dtsi:359 */
			clocks = < &rcc 0x40 0x1 >,
			         < &rcc 0x15 0xff >;    /* in zephyr/dts/arm/st/f4/stm32f4.dtsi:360 */
			resets = < &rctl 0x400 >;       /* in zephyr/dts/arm/st/f4/stm32f4.dtsi:362 */
			interrupts = < 0x1c 0x0 >;      /* in zephyr/dts/arm/st/f4/stm32f4.dtsi:363 */
			interrupt-names = "global";     /* in zephyr/dts/arm/st/f4/stm32f4.dtsi:364 */
			st,prescaler = < 0x0 >;         /* in zephyr/dts/arm/st/f4/stm32f4.dtsi:365 */
			status = "disabled";            /* in zephyr/dts/arm/st/f4/stm32f4.dtsi:366 */

			/* node '/soc/timers@40000000/pwm' defined in zephyr/dts/arm/st/f4/stm32f4.dtsi:368 */
			pwm {
				compatible = "st,stm32-pwm"; /* in zephyr/dts/arm/st/f4/stm32f4.dtsi:369 */
				status = "disabled";         /* in zephyr/dts/arm/st/f4/stm32f4.dtsi:370 */
				#pwm-cells = < 0x3 >;        /* in zephyr/dts/arm/st/f4/stm32f4.dtsi:371 */
			};

			/* node '/soc/timers@40000000/counter' defined in zephyr/dts/arm/st/f4/stm32f4.dtsi:374 */
			counter {
				compatible = "st,stm32-counter"; /* in zephyr/dts/arm/st/f4/stm32f4.dtsi:375 */
				status = "disabled";             /* in zephyr/dts/arm/st/f4/stm32f4.dtsi:376 */
			};

			/* node '/soc/timers@40000000/qdec' defined in zephyr/dts/arm/st/f4/stm32f4.dtsi:379 */
			qdec {
				compatible = "st,stm32-qdec";    /* in zephyr/dts/arm/st/f4/stm32f4.dtsi:380 */
				st,input-filter-level = < 0x0 >; /* in zephyr/dts/arm/st/f4/stm32f4.dtsi:381 */
				status = "disabled";             /* in zephyr/dts/arm/st/f4/stm32f4.dtsi:382 */
			};
		};

		/* node '/soc/timers@40000400' defined in zephyr/dts/arm/st/f4/stm32f4.dtsi:386 */
		timers3: timers@40000400 {
			compatible = "st,stm32-timers"; /* in zephyr/dts/arm/st/f4/stm32f4.dtsi:387 */
			reg = < 0x40000400 0x400 >;     /* in zephyr/dts/arm/st/f4/stm32f4.dtsi:388 */
			clocks = < &rcc 0x40 0x2 >,
			         < &rcc 0x15 0xff >;    /* in zephyr/dts/arm/st/f4/stm32f4.dtsi:389 */
			resets = < &rctl 0x401 >;       /* in zephyr/dts/arm/st/f4/stm32f4.dtsi:391 */
			interrupts = < 0x1d 0x0 >;      /* in zephyr/dts/arm/st/f4/stm32f4.dtsi:392 */
			interrupt-names = "global";     /* in zephyr/dts/arm/st/f4/stm32f4.dtsi:393 */
			st,prescaler = < 0x0 >;         /* in zephyr/dts/arm/st/f4/stm32f4.dtsi:394 */
			status = "okay";                /* in haptic/app.overlay:59 */

			/* node '/soc/timers@40000400/pwm' defined in zephyr/dts/arm/st/f4/stm32f4.dtsi:397 */
			pwm_high: pwm {
				compatible = "st,stm32-pwm";                               /* in zephyr/dts/arm/st/f4/stm32f4.dtsi:398 */
				#pwm-cells = < 0x3 >;                                      /* in zephyr/dts/arm/st/f4/stm32f4.dtsi:400 */
				status = "okay";                                           /* in haptic/app.overlay:61 */
				pinctrl-0 = < &tim3_ch2_pa7 &tim3_ch3_pb0 &tim3_ch4_pb1 >; /* in haptic/app.overlay:62 */
				pinctrl-names = "default";                                 /* in haptic/app.overlay:63 */
			};

			/* node '/soc/timers@40000400/counter' defined in zephyr/dts/arm/st/f4/stm32f4.dtsi:403 */
			counter {
				compatible = "st,stm32-counter"; /* in zephyr/dts/arm/st/f4/stm32f4.dtsi:404 */
				status = "disabled";             /* in zephyr/dts/arm/st/f4/stm32f4.dtsi:405 */
			};

			/* node '/soc/timers@40000400/qdec' defined in zephyr/dts/arm/st/f4/stm32f4.dtsi:408 */
			qdec {
				compatible = "st,stm32-qdec";    /* in zephyr/dts/arm/st/f4/stm32f4.dtsi:409 */
				st,input-filter-level = < 0x0 >; /* in zephyr/dts/arm/st/f4/stm32f4.dtsi:410 */
				status = "disabled";             /* in zephyr/dts/arm/st/f4/stm32f4.dtsi:411 */
			};
		};

		/* node '/soc/timers@40000800' defined in zephyr/dts/arm/st/f4/stm32f4.dtsi:415 */
		timers4: timers@40000800 {
			compatible = "st,stm32-timers"; /* in zephyr/dts/arm/st/f4/stm32f4.dtsi:416 */
			reg = < 0x40000800 0x400 >;     /* in zephyr/dts/arm/st/f4/stm32f4.dtsi:417 */
			clocks = < &rcc 0x40 0x4 >,
			         < &rcc 0x15 0xff >;    /* in zephyr/dts/arm/st/f4/stm32f4.dtsi:418 */
			resets = < &rctl 0x402 >;       /* in zephyr/dts/arm/st/f4/stm32f4.dtsi:420 */
			interrupts = < 0x1e 0x0 >;      /* in zephyr/dts/arm/st/f4/stm32f4.dtsi:421 */
			interrupt-names = "global";     /* in zephyr/dts/arm/st/f4/stm32f4.dtsi:422 */
			st,prescaler = < 0x0 >;         /* in zephyr/dts/arm/st/f4/stm32f4.dtsi:423 */
			status = "okay";                /* in zephyr/boards/weact/blackpill_f411ce/blackpill_f411ce.dts:87 */

			/* node '/soc/timers@40000800/pwm' defined in zephyr/dts/arm/st/f4/stm32f4.dtsi:426 */
			pwm4: pwm {
				compatible = "st,stm32-pwm";                 /* in zephyr/dts/arm/st/f4/stm32f4.dtsi:427 */
				#pwm-cells = < 0x3 >;                        /* in zephyr/dts/arm/st/f4/stm32f4.dtsi:429 */
				status = "okay";                             /* in zephyr/boards/weact/blackpill_f411ce/blackpill_f411ce.dts:90 */
				pinctrl-0 = < &tim4_ch1_pb6 &tim4_ch2_pb7 >; /* in zephyr/boards/weact/blackpill_f411ce/blackpill_f411ce.dts:91 */
				pinctrl-names = "default";                   /* in zephyr/boards/weact/blackpill_f411ce/blackpill_f411ce.dts:92 */
			};

			/* node '/soc/timers@40000800/counter' defined in zephyr/dts/arm/st/f4/stm32f4.dtsi:432 */
			counter {
				compatible = "st,stm32-counter"; /* in zephyr/dts/arm/st/f4/stm32f4.dtsi:433 */
				status = "disabled";             /* in zephyr/dts/arm/st/f4/stm32f4.dtsi:434 */
			};

			/* node '/soc/timers@40000800/qdec' defined in zephyr/dts/arm/st/f4/stm32f4.dtsi:437 */
			qdec {
				compatible = "st,stm32-qdec";    /* in zephyr/dts/arm/st/f4/stm32f4.dtsi:438 */
				st,input-filter-level = < 0x0 >; /* in zephyr/dts/arm/st/f4/stm32f4.dtsi:439 */
				status = "disabled";             /* in zephyr/dts/arm/st/f4/stm32f4.dtsi:440 */
			};
		};

		/* node '/soc/timers@40000c00' defined in zephyr/dts/arm/st/f4/stm32f4.dtsi:444 */
		timers5: timers@40000c00 {
			compatible = "st,stm32-timers"; /* in zephyr/dts/arm/st/f4/stm32f4.dtsi:445 */
			reg = < 0x40000c00 0x400 >;     /* in zephyr/dts/arm/st/f4/stm32f4.dtsi:446 */
			clocks = < &rcc 0x40 0x8 >,
			         < &rcc 0x15 0xff >;    /* in zephyr/dts/arm/st/f4/stm32f4.dtsi:447 */
			resets = < &rctl 0x403 >;       /* in zephyr/dts/arm/st/f4/stm32f4.dtsi:449 */
			interrupts = < 0x32 0x0 >;      /* in zephyr/dts/arm/st/f4/stm32f4.dtsi:450 */
			interrupt-names = "global";     /* in zephyr/dts/arm/st/f4/stm32f4.dtsi:451 */
			st,prescaler = < 0x0 >;         /* in zephyr/dts/arm/st/f4/stm32f4.dtsi:452 */
			status = "disabled";            /* in zephyr/dts/arm/st/f4/stm32f4.dtsi:453 */

			/* node '/soc/timers@40000c00/pwm' defined in zephyr/dts/arm/st/f4/stm32f4.dtsi:455 */
			pwm {
				compatible = "st,stm32-pwm"; /* in zephyr/dts/arm/st/f4/stm32f4.dtsi:456 */
				status = "disabled";         /* in zephyr/dts/arm/st/f4/stm32f4.dtsi:457 */
				#pwm-cells = < 0x3 >;        /* in zephyr/dts/arm/st/f4/stm32f4.dtsi:458 */
			};

			/* node '/soc/timers@40000c00/counter' defined in zephyr/dts/arm/st/f4/stm32f4.dtsi:461 */
			counter {
				compatible = "st,stm32-counter"; /* in zephyr/dts/arm/st/f4/stm32f4.dtsi:462 */
				status = "disabled";             /* in zephyr/dts/arm/st/f4/stm32f4.dtsi:463 */
			};

			/* node '/soc/timers@40000c00/qdec' defined in zephyr/dts/arm/st/f4/stm32f4.dtsi:466 */
			qdec {
				compatible = "st,stm32-qdec";    /* in zephyr/dts/arm/st/f4/stm32f4.dtsi:467 */
				st,input-filter-level = < 0x0 >; /* in zephyr/dts/arm/st/f4/stm32f4.dtsi:468 */
				status = "disabled";             /* in zephyr/dts/arm/st/f4/stm32f4.dtsi:469 */
			};
		};

		/* node '/soc/timers@40014000' defined in zephyr/dts/arm/st/f4/stm32f4.dtsi:473 */
		timers9: timers@40014000 {
			compatible = "st,stm32-timers"; /* in zephyr/dts/arm/st/f4/stm32f4.dtsi:474 */
			reg = < 0x40014000 0x400 >;     /* in zephyr/dts/arm/st/f4/stm32f4.dtsi:475 */
			clocks = < &rcc 0x44 0x10000 >,
			         < &rcc 0x16 0xff >;    /* in zephyr/dts/arm/st/f4/stm32f4.dtsi:476 */
			resets = < &rctl 0x490 >;       /* in zephyr/dts/arm/st/f4/stm32f4.dtsi:478 */
			interrupts = < 0x18 0x0 >;      /* in zephyr/dts/arm/st/f4/stm32f4.dtsi:479 */
			interrupt-names = "global";     /* in zephyr/dts/arm/st/f4/stm32f4.dtsi:480 */
			st,prescaler = < 0x0 >;         /* in zephyr/dts/arm/st/f4/stm32f4.dtsi:481 */
			status = "disabled";            /* in zephyr/dts/arm/st/f4/stm32f4.dtsi:482 */

			/* node '/soc/timers@40014000/pwm' defined in zephyr/dts/arm/st/f4/stm32f4.dtsi:484 */
			pwm {
				compatible = "st,stm32-pwm"; /* in zephyr/dts/arm/st/f4/stm32f4.dtsi:485 */
				status = "disabled";         /* in zephyr/dts/arm/st/f4/stm32f4.dtsi:486 */
				#pwm-cells = < 0x3 >;        /* in zephyr/dts/arm/st/f4/stm32f4.dtsi:487 */
			};

			/* node '/soc/timers@40014000/counter' defined in zephyr/dts/arm/st/f4/stm32f4.dtsi:490 */
			counter {
				compatible = "st,stm32-counter"; /* in zephyr/dts/arm/st/f4/stm32f4.dtsi:491 */
				status = "disabled";             /* in zephyr/dts/arm/st/f4/stm32f4.dtsi:492 */
			};
		};

		/* node '/soc/timers@40014400' defined in zephyr/dts/arm/st/f4/stm32f4.dtsi:496 */
		timers10: timers@40014400 {
			compatible = "st,stm32-timers"; /* in zephyr/dts/arm/st/f4/stm32f4.dtsi:497 */
			reg = < 0x40014400 0x400 >;     /* in zephyr/dts/arm/st/f4/stm32f4.dtsi:498 */
			clocks = < &rcc 0x44 0x20000 >,
			         < &rcc 0x16 0xff >;    /* in zephyr/dts/arm/st/f4/stm32f4.dtsi:499 */
			resets = < &rctl 0x491 >;       /* in zephyr/dts/arm/st/f4/stm32f4.dtsi:501 */
			interrupts = < 0x19 0x0 >;      /* in zephyr/dts/arm/st/f4/stm32f4.dtsi:502 */
			interrupt-names = "global";     /* in zephyr/dts/arm/st/f4/stm32f4.dtsi:503 */
			st,prescaler = < 0x0 >;         /* in zephyr/dts/arm/st/f4/stm32f4.dtsi:504 */
			status = "disabled";            /* in zephyr/dts/arm/st/f4/stm32f4.dtsi:505 */

			/* node '/soc/timers@40014400/pwm' defined in zephyr/dts/arm/st/f4/stm32f4.dtsi:507 */
			pwm {
				compatible = "st,stm32-pwm"; /* in zephyr/dts/arm/st/f4/stm32f4.dtsi:508 */
				status = "disabled";         /* in zephyr/dts/arm/st/f4/stm32f4.dtsi:509 */
				#pwm-cells = < 0x3 >;        /* in zephyr/dts/arm/st/f4/stm32f4.dtsi:510 */
			};

			/* node '/soc/timers@40014400/counter' defined in zephyr/dts/arm/st/f4/stm32f4.dtsi:513 */
			counter {
				compatible = "st,stm32-counter"; /* in zephyr/dts/arm/st/f4/stm32f4.dtsi:514 */
				status = "disabled";             /* in zephyr/dts/arm/st/f4/stm32f4.dtsi:515 */
			};
		};

		/* node '/soc/timers@40014800' defined in zephyr/dts/arm/st/f4/stm32f4.dtsi:519 */
		timers11: timers@40014800 {
			compatible = "st,stm32-timers"; /* in zephyr/dts/arm/st/f4/stm32f4.dtsi:520 */
			reg = < 0x40014800 0x400 >;     /* in zephyr/dts/arm/st/f4/stm32f4.dtsi:521 */
			clocks = < &rcc 0x44 0x40000 >,
			         < &rcc 0x16 0xff >;    /* in zephyr/dts/arm/st/f4/stm32f4.dtsi:522 */
			resets = < &rctl 0x492 >;       /* in zephyr/dts/arm/st/f4/stm32f4.dtsi:524 */
			interrupts = < 0x1a 0x0 >;      /* in zephyr/dts/arm/st/f4/stm32f4.dtsi:525 */
			interrupt-names = "global";     /* in zephyr/dts/arm/st/f4/stm32f4.dtsi:526 */
			st,prescaler = < 0x0 >;         /* in zephyr/dts/arm/st/f4/stm32f4.dtsi:527 */
			status = "disabled";            /* in zephyr/dts/arm/st/f4/stm32f4.dtsi:528 */

			/* node '/soc/timers@40014800/pwm' defined in zephyr/dts/arm/st/f4/stm32f4.dtsi:530 */
			pwm {
				compatible = "st,stm32-pwm"; /* in zephyr/dts/arm/st/f4/stm32f4.dtsi:531 */
				status = "disabled";         /* in zephyr/dts/arm/st/f4/stm32f4.dtsi:532 */
				#pwm-cells = < 0x3 >;        /* in zephyr/dts/arm/st/f4/stm32f4.dtsi:533 */
			};

			/* node '/soc/timers@40014800/counter' defined in zephyr/dts/arm/st/f4/stm32f4.dtsi:536 */
			counter {
				compatible = "st,stm32-counter"; /* in zephyr/dts/arm/st/f4/stm32f4.dtsi:537 */
				status = "disabled";             /* in zephyr/dts/arm/st/f4/stm32f4.dtsi:538 */
			};
		};

		/* node '/soc/rtc@40002800' defined in zephyr/dts/arm/st/f4/stm32f4.dtsi:542 */
		rtc: rtc@40002800 {
			compatible = "st,stm32-rtc";       /* in zephyr/dts/arm/st/f4/stm32f4.dtsi:543 */
			reg = < 0x40002800 0x400 >;        /* in zephyr/dts/arm/st/f4/stm32f4.dtsi:544 */
			interrupts = < 0x29 0x0 >;         /* in zephyr/dts/arm/st/f4/stm32f4.dtsi:545 */
			prescaler = < 0x8000 >;            /* in zephyr/dts/arm/st/f4/stm32f4.dtsi:547 */
			alarms-count = < 0x2 >;            /* in zephyr/dts/arm/st/f4/stm32f4.dtsi:548 */
			alrm-exti-line = < 0x11 >;         /* in zephyr/dts/arm/st/f4/stm32f4.dtsi:549 */
			clocks = < &rcc 0x40 0x10000000 >,
			         < &rcc 0x3 0x2280070 >;   /* in zephyr/boards/weact/blackpill_f411ce/blackpill_f411ce.dts:118 */
			status = "okay";                   /* in zephyr/boards/weact/blackpill_f411ce/blackpill_f411ce.dts:120 */

			/* node '/soc/rtc@40002800/backup_regs' defined in zephyr/dts/arm/st/f4/stm32f4.dtsi:552 */
			bbram: backup_regs {
				compatible = "st,stm32-bbram"; /* in zephyr/dts/arm/st/f4/stm32f4.dtsi:553 */
				st,backup-regs = < 0x14 >;     /* in zephyr/dts/arm/st/f4/stm32f4.dtsi:554 */
				status = "disabled";           /* in zephyr/dts/arm/st/f4/stm32f4.dtsi:555 */
			};
		};

		/* node '/soc/adc@40012000' defined in zephyr/dts/arm/st/f4/stm32f4.dtsi:559 */
		adc1: adc@40012000 {
			compatible = "st,stm32f4-adc",
			             "st,stm32-adc";                                 /* in zephyr/dts/arm/st/f4/stm32f4.dtsi:560 */
			reg = < 0x40012000 0x400 >;                                  /* in zephyr/dts/arm/st/f4/stm32f4.dtsi:561 */
			clocks = < &rcc 0x44 0x100 >;                                /* in zephyr/dts/arm/st/f4/stm32f4.dtsi:562 */
			clock-names = "adcx";                                        /* in zephyr/dts/arm/st/f4/stm32f4.dtsi:563 */
			interrupts = < 0x12 0x0 >;                                   /* in zephyr/dts/arm/st/f4/stm32f4.dtsi:564 */
			#io-channel-cells = < 0x1 >;                                 /* in zephyr/dts/arm/st/f4/stm32f4.dtsi:565 */
			st,adc-resolutions = < 0xc 0xa 0x8 0x6 >;                    /* in zephyr/dts/arm/st/f4/stm32f4.dtsi:566 */
			sampling-times = < 0x3 0xf 0x1c 0x38 0x54 0x70 0x90 0x1e0 >; /* in zephyr/dts/arm/st/f4/stm32f4.dtsi:567 */
			st,adc-sequencer = "programmable";                           /* in zephyr/dts/arm/st/f4/stm32f4.dtsi:569 */
			st,adc-oversampler = "none";                                 /* in zephyr/dts/arm/st/f4/stm32f4.dtsi:570 */
			st,adc-internal-regulator = "none";                          /* in zephyr/dts/arm/st/f4/stm32f4.dtsi:571 */
			pinctrl-0 = < &adc1_in1_pa1 >;                               /* in zephyr/boards/weact/blackpill_f411ce/blackpill_f411ce.dts:130 */
			pinctrl-names = "default";                                   /* in zephyr/boards/weact/blackpill_f411ce/blackpill_f411ce.dts:131 */
			st,adc-clock-source = "SYNC";                                /* in zephyr/boards/weact/blackpill_f411ce/blackpill_f411ce.dts:132 */
			st,adc-prescaler = < 0x2 >;                                  /* in zephyr/boards/weact/blackpill_f411ce/blackpill_f411ce.dts:133 */
			status = "okay";                                             /* in zephyr/boards/weact/blackpill_f411ce/blackpill_f411ce.dts:134 */
			phandle = < 0x1d >;                                          /* in zephyr/dts/arm/st/f4/stm32f411.dtsi:65 */
		};

		/* node '/soc/dma@40026000' defined in zephyr/dts/arm/st/f4/stm32f4.dtsi:575 */
		dma1: dma@40026000 {
			compatible = "st,stm32-dma-v1";                                                      /* in zephyr/dts/arm/st/f4/stm32f4.dtsi:576 */
			#dma-cells = < 0x4 >;                                                                /* in zephyr/dts/arm/st/f4/stm32f4.dtsi:577 */
			reg = < 0x40026000 0x400 >;                                                          /* in zephyr/dts/arm/st/f4/stm32f4.dtsi:578 */
			interrupts = < 0xb 0x0 0xc 0x0 0xd 0x0 0xe 0x0 0xf 0x0 0x10 0x0 0x11 0x0 0x2f 0x0 >; /* in zephyr/dts/arm/st/f4/stm32f4.dtsi:579 */
			clocks = < &rcc 0x30 0x200000 >;                                                     /* in zephyr/dts/arm/st/f4/stm32f4.dtsi:580 */
			status = "disabled";                                                                 /* in zephyr/dts/arm/st/f4/stm32f4.dtsi:581 */
			phandle = < 0x19 >;                                                                  /* in zephyr/dts/arm/st/f4/stm32f401.dtsi:61 */
		};

		/* node '/soc/dma@40026400' defined in zephyr/dts/arm/st/f4/stm32f4.dtsi:584 */
		dma2: dma@40026400 {
			compatible = "st,stm32-dma-v1";                                                           /* in zephyr/dts/arm/st/f4/stm32f4.dtsi:585 */
			#dma-cells = < 0x4 >;                                                                     /* in zephyr/dts/arm/st/f4/stm32f4.dtsi:586 */
			reg = < 0x40026400 0x400 >;                                                               /* in zephyr/dts/arm/st/f4/stm32f4.dtsi:587 */
			interrupts = < 0x38 0x0 0x39 0x0 0x3a 0x0 0x3b 0x0 0x3c 0x0 0x44 0x0 0x45 0x0 0x46 0x0 >; /* in zephyr/dts/arm/st/f4/stm32f4.dtsi:588 */
			clocks = < &rcc 0x30 0x400000 >;                                                          /* in zephyr/dts/arm/st/f4/stm32f4.dtsi:589 */
			st,mem2mem;                                                                               /* in zephyr/dts/arm/st/f4/stm32f4.dtsi:590 */
			status = "disabled";                                                                      /* in zephyr/dts/arm/st/f4/stm32f4.dtsi:591 */
			phandle = < 0x1a >;                                                                       /* in zephyr/dts/arm/st/f4/stm32f411.dtsi:31 */
		};

		/* node '/soc/sdmmc@40012c00' defined in zephyr/dts/arm/st/f4/stm32f4.dtsi:594 */
		sdmmc1: sdmmc@40012c00 {
			compatible = "st,stm32-sdmmc"; /* in zephyr/dts/arm/st/f4/stm32f4.dtsi:595 */
			reg = < 0x40012c00 0x400 >;    /* in zephyr/dts/arm/st/f4/stm32f4.dtsi:596 */
			clocks = < &rcc 0x44 0x800 >,
			         < &rcc 0x7 0xff >;    /* in zephyr/dts/arm/st/f4/stm32f4.dtsi:597 */
			resets = < &rctl 0x48b >;      /* in zephyr/dts/arm/st/f4/stm32f4.dtsi:599 */
			interrupts = < 0x31 0x0 >;     /* in zephyr/dts/arm/st/f4/stm32f4.dtsi:600 */
			status = "disabled";           /* in zephyr/dts/arm/st/f4/stm32f4.dtsi:601 */
		};

		/* node '/soc/spi@40003800' defined in zephyr/dts/arm/st/f4/stm32f401.dtsi:21 */
		spi2: spi@40003800 {
			compatible = "st,stm32-spi";            /* in zephyr/dts/arm/st/f4/stm32f401.dtsi:22 */
			#address-cells = < 0x1 >;               /* in zephyr/dts/arm/st/f4/stm32f401.dtsi:23 */
			#size-cells = < 0x0 >;                  /* in zephyr/dts/arm/st/f4/stm32f401.dtsi:24 */
			reg = < 0x40003800 0x400 >;             /* in zephyr/dts/arm/st/f4/stm32f401.dtsi:25 */
			clocks = < &rcc 0x40 0x4000 >;          /* in zephyr/dts/arm/st/f4/stm32f401.dtsi:26 */
			interrupts = < 0x24 0x5 >;              /* in zephyr/dts/arm/st/f4/stm32f401.dtsi:27 */
			st,spi-data-width = "limited-8-16-bit"; /* in zephyr/dts/arm/st/f4/stm32f401.dtsi:28 */
			status = "disabled";                    /* in zephyr/dts/arm/st/f4/stm32f401.dtsi:29 */
		};

		/* node '/soc/spi@40003c00' defined in zephyr/dts/arm/st/f4/stm32f401.dtsi:32 */
		spi3: spi@40003c00 {
			compatible = "st,stm32-spi";            /* in zephyr/dts/arm/st/f4/stm32f401.dtsi:33 */
			#address-cells = < 0x1 >;               /* in zephyr/dts/arm/st/f4/stm32f401.dtsi:34 */
			#size-cells = < 0x0 >;                  /* in zephyr/dts/arm/st/f4/stm32f401.dtsi:35 */
			reg = < 0x40003c00 0x400 >;             /* in zephyr/dts/arm/st/f4/stm32f401.dtsi:36 */
			clocks = < &rcc 0x40 0x8000 >;          /* in zephyr/dts/arm/st/f4/stm32f401.dtsi:37 */
			interrupts = < 0x33 0x5 >;              /* in zephyr/dts/arm/st/f4/stm32f401.dtsi:38 */
			st,spi-data-width = "limited-8-16-bit"; /* in zephyr/dts/arm/st/f4/stm32f401.dtsi:39 */
			status = "disabled";                    /* in zephyr/dts/arm/st/f4/stm32f401.dtsi:40 */
		};

		/* node '/soc/spi@40013400' defined in zephyr/dts/arm/st/f4/stm32f401.dtsi:43 */
		spi4: spi@40013400 {
			compatible = "st,stm32-spi";            /* in zephyr/dts/arm/st/f4/stm32f401.dtsi:44 */
			#address-cells = < 0x1 >;               /* in zephyr/dts/arm/st/f4/stm32f401.dtsi:45 */
			#size-cells = < 0x0 >;                  /* in zephyr/dts/arm/st/f4/stm32f401.dtsi:46 */
			reg = < 0x40013400 0x400 >;             /* in zephyr/dts/arm/st/f4/stm32f401.dtsi:47 */
			clocks = < &rcc 0x44 0x2000 >;          /* in zephyr/dts/arm/st/f4/stm32f401.dtsi:48 */
			interrupts = < 0x54 0x5 >;              /* in zephyr/dts/arm/st/f4/stm32f401.dtsi:49 */
			st,spi-data-width = "limited-8-16-bit"; /* in zephyr/dts/arm/st/f4/stm32f401.dtsi:50 */
			status = "disabled";                    /* in zephyr/dts/arm/st/f4/stm32f401.dtsi:51 */
		};

		/* node '/soc/i2s@40003800' defined in zephyr/dts/arm/st/f4/stm32f401.dtsi:54 */
		i2s2: i2s@40003800 {
			compatible = "st,stm32-i2s";        /* in zephyr/dts/arm/st/f4/stm32f401.dtsi:55 */
			#address-cells = < 0x1 >;           /* in zephyr/dts/arm/st/f4/stm32f401.dtsi:56 */
			#size-cells = < 0x0 >;              /* in zephyr/dts/arm/st/f4/stm32f401.dtsi:57 */
			reg = < 0x40003800 0x400 >;         /* in zephyr/dts/arm/st/f4/stm32f401.dtsi:58 */
			clocks = < &rcc 0x40 0x4000 >;      /* in zephyr/dts/arm/st/f4/stm32f401.dtsi:59 */
			interrupts = < 0x24 0x5 >;          /* in zephyr/dts/arm/st/f4/stm32f401.dtsi:60 */
			dmas = < &dma1 0x4 0x0 0x400 0x3 >,
			       < &dma1 0x3 0x0 0x400 0x3 >; /* in zephyr/dts/arm/st/f4/stm32f401.dtsi:61 */
			dma-names = "tx",
			            "rx";                   /* in zephyr/dts/arm/st/f4/stm32f401.dtsi:63 */
			status = "disabled";                /* in zephyr/dts/arm/st/f4/stm32f401.dtsi:64 */
		};

		/* node '/soc/i2s@40003c00' defined in zephyr/dts/arm/st/f4/stm32f401.dtsi:67 */
		i2s3: i2s@40003c00 {
			compatible = "st,stm32-i2s";        /* in zephyr/dts/arm/st/f4/stm32f401.dtsi:68 */
			#address-cells = < 0x1 >;           /* in zephyr/dts/arm/st/f4/stm32f401.dtsi:69 */
			#size-cells = < 0x0 >;              /* in zephyr/dts/arm/st/f4/stm32f401.dtsi:70 */
			reg = < 0x40003c00 0x400 >;         /* in zephyr/dts/arm/st/f4/stm32f401.dtsi:71 */
			clocks = < &rcc 0x40 0x8000 >;      /* in zephyr/dts/arm/st/f4/stm32f401.dtsi:72 */
			interrupts = < 0x33 0x5 >;          /* in zephyr/dts/arm/st/f4/stm32f401.dtsi:73 */
			dmas = < &dma1 0x5 0x0 0x400 0x3 >,
			       < &dma1 0x0 0x0 0x400 0x3 >; /* in zephyr/dts/arm/st/f4/stm32f401.dtsi:74 */
			dma-names = "tx",
			            "rx";                   /* in zephyr/dts/arm/st/f4/stm32f401.dtsi:76 */
			status = "disabled";                /* in zephyr/dts/arm/st/f4/stm32f401.dtsi:77 */
		};

		/* node '/soc/spi@40015000' defined in zephyr/dts/arm/st/f4/stm32f411.dtsi:13 */
		spi5: spi@40015000 {
			compatible = "st,stm32-spi";            /* in zephyr/dts/arm/st/f4/stm32f411.dtsi:14 */
			#address-cells = < 0x1 >;               /* in zephyr/dts/arm/st/f4/stm32f411.dtsi:15 */
			#size-cells = < 0x0 >;                  /* in zephyr/dts/arm/st/f4/stm32f411.dtsi:16 */
			reg = < 0x40015000 0x400 >;             /* in zephyr/dts/arm/st/f4/stm32f411.dtsi:17 */
			clocks = < &rcc 0x44 0x100000 >;        /* in zephyr/dts/arm/st/f4/stm32f411.dtsi:18 */
			interrupts = < 0x55 0x5 >;              /* in zephyr/dts/arm/st/f4/stm32f411.dtsi:19 */
			st,spi-data-width = "limited-8-16-bit"; /* in zephyr/dts/arm/st/f4/stm32f411.dtsi:20 */
			status = "disabled";                    /* in zephyr/dts/arm/st/f4/stm32f411.dtsi:21 */
		};

		/* node '/soc/i2s@40013000' defined in zephyr/dts/arm/st/f4/stm32f411.dtsi:24 */
		i2s1: i2s@40013000 {
			compatible = "st,stm32-i2s";        /* in zephyr/dts/arm/st/f4/stm32f411.dtsi:25 */
			#address-cells = < 0x1 >;           /* in zephyr/dts/arm/st/f4/stm32f411.dtsi:26 */
			#size-cells = < 0x0 >;              /* in zephyr/dts/arm/st/f4/stm32f411.dtsi:27 */
			reg = < 0x40013000 0x400 >;         /* in zephyr/dts/arm/st/f4/stm32f411.dtsi:28 */
			clocks = < &rcc 0x44 0x1000 >;      /* in zephyr/dts/arm/st/f4/stm32f411.dtsi:29 */
			interrupts = < 0x23 0x5 >;          /* in zephyr/dts/arm/st/f4/stm32f411.dtsi:30 */
			dmas = < &dma2 0x3 0x3 0x400 0x3 >,
			       < &dma2 0x2 0x3 0x400 0x3 >; /* in zephyr/dts/arm/st/f4/stm32f411.dtsi:31 */
			dma-names = "tx",
			            "rx";                   /* in zephyr/dts/arm/st/f4/stm32f411.dtsi:33 */
			status = "disabled";                /* in zephyr/dts/arm/st/f4/stm32f411.dtsi:34 */
		};

		/* node '/soc/i2s@40013400' defined in zephyr/dts/arm/st/f4/stm32f411.dtsi:37 */
		i2s4: i2s@40013400 {
			compatible = "st,stm32-i2s";        /* in zephyr/dts/arm/st/f4/stm32f411.dtsi:38 */
			#address-cells = < 0x1 >;           /* in zephyr/dts/arm/st/f4/stm32f411.dtsi:39 */
			#size-cells = < 0x0 >;              /* in zephyr/dts/arm/st/f4/stm32f411.dtsi:40 */
			reg = < 0x40013400 0x400 >;         /* in zephyr/dts/arm/st/f4/stm32f411.dtsi:41 */
			clocks = < &rcc 0x44 0x2000 >;      /* in zephyr/dts/arm/st/f4/stm32f411.dtsi:42 */
			interrupts = < 0x54 0x5 >;          /* in zephyr/dts/arm/st/f4/stm32f411.dtsi:43 */
			dmas = < &dma2 0x1 0x4 0x400 0x3 >,
			       < &dma2 0x0 0x4 0x400 0x3 >; /* in zephyr/dts/arm/st/f4/stm32f411.dtsi:44 */
			dma-names = "tx",
			            "rx";                   /* in zephyr/dts/arm/st/f4/stm32f411.dtsi:46 */
			status = "disabled";                /* in zephyr/dts/arm/st/f4/stm32f411.dtsi:47 */
		};

		/* node '/soc/i2s@40015000' defined in zephyr/dts/arm/st/f4/stm32f411.dtsi:50 */
		i2s5: i2s@40015000 {
			compatible = "st,stm32-i2s";        /* in zephyr/dts/arm/st/f4/stm32f411.dtsi:51 */
			#address-cells = < 0x1 >;           /* in zephyr/dts/arm/st/f4/stm32f411.dtsi:52 */
			#size-cells = < 0x0 >;              /* in zephyr/dts/arm/st/f4/stm32f411.dtsi:53 */
			reg = < 0x40015000 0x400 >;         /* in zephyr/dts/arm/st/f4/stm32f411.dtsi:54 */
			clocks = < &rcc 0x44 0x100000 >;    /* in zephyr/dts/arm/st/f4/stm32f411.dtsi:55 */
			interrupts = < 0x55 0x5 >;          /* in zephyr/dts/arm/st/f4/stm32f411.dtsi:56 */
			dmas = < &dma2 0x6 0x7 0x400 0x3 >,
			       < &dma2 0x5 0x7 0x400 0x3 >; /* in zephyr/dts/arm/st/f4/stm32f411.dtsi:57 */
			dma-names = "tx",
			            "rx";                   /* in zephyr/dts/arm/st/f4/stm32f411.dtsi:59 */
			status = "disabled";                /* in zephyr/dts/arm/st/f4/stm32f411.dtsi:60 */
		};
	};

	/* node '/cpus' defined in zephyr/dts/arm/st/f4/stm32f4.dtsi:30 */
	cpus {
		#address-cells = < 0x1 >; /* in zephyr/dts/arm/st/f4/stm32f4.dtsi:31 */
		#size-cells = < 0x0 >;    /* in zephyr/dts/arm/st/f4/stm32f4.dtsi:32 */

		/* node '/cpus/cpu@0' defined in zephyr/dts/arm/st/f4/stm32f4.dtsi:34 */
		cpu0: cpu@0 {
			device_type = "cpu";           /* in zephyr/dts/arm/st/f4/stm32f4.dtsi:35 */
			compatible = "arm,cortex-m4f"; /* in zephyr/dts/arm/st/f4/stm32f4.dtsi:36 */
			reg = < 0x0 >;                 /* in zephyr/dts/arm/st/f4/stm32f4.dtsi:37 */
			cpu-power-states = < &stop >;  /* in zephyr/dts/arm/st/f4/stm32f4.dtsi:38 */
		};

		/* node '/cpus/power-states' defined in zephyr/dts/arm/st/f4/stm32f4.dtsi:41 */
		power-states {

			/* node '/cpus/power-states/stop' defined in zephyr/dts/arm/st/f4/stm32f4.dtsi:42 */
			stop: stop {
				compatible = "zephyr,power-state";    /* in zephyr/dts/arm/st/f4/stm32f4.dtsi:43 */
				power-state-name = "suspend-to-idle"; /* in zephyr/dts/arm/st/f4/stm32f4.dtsi:44 */
				min-residency-us = < 0x190 >;         /* in zephyr/dts/arm/st/f4/stm32f4.dtsi:51 */
				exit-latency-us = < 0x12c >;          /* in zephyr/dts/arm/st/f4/stm32f4.dtsi:52 */
				phandle = < 0x1b >;                   /* in zephyr/dts/arm/st/f4/stm32f4.dtsi:38 */
			};
		};
	};

	/* node '/memory@20000000' defined in zephyr/dts/arm/st/f4/stm32f4.dtsi:57 */
	sram0: memory@20000000 {
		compatible = "zephyr,memory-region",
		             "mmio-sram";            /* in zephyr/dts/arm/st/f4/stm32f4.dtsi:58 */
		zephyr,memory-region = "SRAM0";      /* in zephyr/dts/arm/st/f4/stm32f4.dtsi:59 */
		reg = < 0x20000000 0x20000 >;        /* in zephyr/dts/arm/st/f4/stm32f411Xe.dtsi:11 */
	};

	/* node '/clocks' defined in zephyr/dts/arm/st/f4/stm32f4.dtsi:62 */
	clocks {

		/* node '/clocks/clk-hse' defined in zephyr/dts/arm/st/f4/stm32f4.dtsi:63 */
		clk_hse: clk-hse {
			#clock-cells = < 0x0 >;            /* in zephyr/dts/arm/st/f4/stm32f4.dtsi:64 */
			compatible = "st,stm32-hse-clock"; /* in zephyr/dts/arm/st/f4/stm32f4.dtsi:65 */
			clock-frequency = < 0x17d7840 >;   /* in zephyr/boards/weact/blackpill_f411ce/blackpill_f411ce.dts:142 */
			status = "okay";                   /* in zephyr/boards/weact/blackpill_f411ce/blackpill_f411ce.dts:143 */
			phandle = < 0x1c >;                /* in zephyr/boards/weact/blackpill_f411ce/blackpill_f411ce.dts:151 */
		};

		/* node '/clocks/clk-hsi' defined in zephyr/dts/arm/st/f4/stm32f4.dtsi:69 */
		clk_hsi: clk-hsi {
			#clock-cells = < 0x0 >;         /* in zephyr/dts/arm/st/f4/stm32f4.dtsi:70 */
			compatible = "fixed-clock";     /* in zephyr/dts/arm/st/f4/stm32f4.dtsi:71 */
			clock-frequency = < 0xf42400 >; /* in zephyr/dts/arm/st/f4/stm32f4.dtsi:72 */
			status = "disabled";            /* in zephyr/dts/arm/st/f4/stm32f4.dtsi:73 */
		};

		/* node '/clocks/clk-lse' defined in zephyr/dts/arm/st/f4/stm32f4.dtsi:76 */
		clk_lse: clk-lse {
			#clock-cells = < 0x0 >;       /* in zephyr/dts/arm/st/f4/stm32f4.dtsi:77 */
			compatible = "fixed-clock";   /* in zephyr/dts/arm/st/f4/stm32f4.dtsi:78 */
			clock-frequency = < 0x8000 >; /* in zephyr/dts/arm/st/f4/stm32f4.dtsi:79 */
			status = "disabled";          /* in zephyr/dts/arm/st/f4/stm32f4.dtsi:80 */
		};

		/* node '/clocks/clk-lsi' defined in zephyr/dts/arm/st/f4/stm32f4.dtsi:83 */
		clk_lsi: clk-lsi {
			#clock-cells = < 0x0 >;       /* in zephyr/dts/arm/st/f4/stm32f4.dtsi:84 */
			compatible = "fixed-clock";   /* in zephyr/dts/arm/st/f4/stm32f4.dtsi:85 */
			clock-frequency = < 0x7d00 >; /* in zephyr/dts/arm/st/f4/stm32f4.dtsi:86 */
			status = "okay";              /* in zephyr/boards/weact/blackpill_f411ce/blackpill_f411ce.dts:138 */
		};

		/* node '/clocks/pll' defined in zephyr/dts/arm/st/f4/stm32f4.dtsi:90 */
		pll: pll {
			#clock-cells = < 0x0 >;              /* in zephyr/dts/arm/st/f4/stm32f4.dtsi:91 */
			compatible = "st,stm32fx-pll-clock"; /* in zephyr/dts/arm/st/f4/stm32f4.dtsi:92 */
			div-m = < 0x19 >;                    /* in zephyr/boards/weact/blackpill_f411ce/blackpill_f411ce.dts:147 */
			mul-n = < 0xc0 >;                    /* in zephyr/boards/weact/blackpill_f411ce/blackpill_f411ce.dts:148 */
			div-p = < 0x2 >;                     /* in zephyr/boards/weact/blackpill_f411ce/blackpill_f411ce.dts:149 */
			div-q = < 0x4 >;                     /* in zephyr/boards/weact/blackpill_f411ce/blackpill_f411ce.dts:150 */
			clocks = < &clk_hse >;               /* in zephyr/boards/weact/blackpill_f411ce/blackpill_f411ce.dts:151 */
			status = "okay";                     /* in zephyr/boards/weact/blackpill_f411ce/blackpill_f411ce.dts:152 */
			phandle = < 0x2 >;                   /* in zephyr/boards/weact/blackpill_f411ce/blackpill_f411ce.dts:156 */
		};

		/* node '/clocks/plli2s' defined in zephyr/dts/arm/st/f4/stm32f401.dtsi:11 */
		plli2s: plli2s {
			#clock-cells = < 0x0 >;              /* in zephyr/dts/arm/st/f4/stm32f401.dtsi:12 */
			compatible = "st,stm32fx-pll-clock"; /* in zephyr/dts/arm/st/f4/stm32f401.dtsi:13 */
			status = "disabled";                 /* in zephyr/dts/arm/st/f4/stm32f401.dtsi:14 */
		};
	};

	/* node '/mcos' defined in zephyr/dts/arm/st/f4/stm32f4.dtsi:97 */
	mcos {

		/* node '/mcos/mco1' defined in zephyr/dts/arm/st/f4/stm32f4.dtsi:98 */
		mco1: mco1 {
			compatible = "st,stm32-clock-mco"; /* in zephyr/dts/arm/st/f4/stm32f4.dtsi:99 */
			status = "disabled";               /* in zephyr/dts/arm/st/f4/stm32f4.dtsi:100 */
		};

		/* node '/mcos/mco2' defined in zephyr/dts/arm/st/f4/stm32f4.dtsi:103 */
		mco2: mco2 {
			compatible = "st,stm32-clock-mco"; /* in zephyr/dts/arm/st/f4/stm32f4.dtsi:104 */
			status = "disabled";               /* in zephyr/dts/arm/st/f4/stm32f4.dtsi:105 */
		};
	};

	/* node '/power@40007000' defined in zephyr/dts/arm/st/f4/stm32f4.dtsi:605 */
	pwr: power@40007000 {
		compatible = "st,stm32-pwr"; /* in zephyr/dts/arm/st/f4/stm32f4.dtsi:606 */
		reg = < 0x40007000 0x400 >;  /* in zephyr/dts/arm/st/f4/stm32f4.dtsi:607 */
		status = "disabled";         /* in zephyr/dts/arm/st/f4/stm32f4.dtsi:608 */
		wkup-pins-nb = < 0x1 >;      /* in zephyr/dts/arm/st/f4/stm32f4.dtsi:610 */
		#address-cells = < 0x1 >;    /* in zephyr/dts/arm/st/f4/stm32f4.dtsi:612 */
		#size-cells = < 0x0 >;       /* in zephyr/dts/arm/st/f4/stm32f4.dtsi:613 */

		/* node '/power@40007000/wkup-pin@1' defined in zephyr/dts/arm/st/f4/stm32f4.dtsi:615 */
		wkup-pin@1 {
			reg = < 0x1 >;                   /* in zephyr/dts/arm/st/f4/stm32f4.dtsi:616 */
			wkup-gpios = < &gpioa 0x0 0x1 >; /* in zephyr/dts/arm/st/f4/stm32f4.dtsi:617 */
		};
	};

	/* node '/dietemp' defined in zephyr/dts/arm/st/f4/stm32f4.dtsi:621 */
	die_temp: dietemp {
		compatible = "st,stm32-temp-cal"; /* in zephyr/dts/arm/st/f4/stm32f4.dtsi:622 */
		ts-cal1-addr = < 0x1fff7a2c >;    /* in zephyr/dts/arm/st/f4/stm32f4.dtsi:623 */
		ts-cal2-addr = < 0x1fff7a2e >;    /* in zephyr/dts/arm/st/f4/stm32f4.dtsi:624 */
		ts-cal1-temp = < 0x1e >;          /* in zephyr/dts/arm/st/f4/stm32f4.dtsi:625 */
		ts-cal2-temp = < 0x6e >;          /* in zephyr/dts/arm/st/f4/stm32f4.dtsi:626 */
		ts-cal-vrefanalog = < 0xce4 >;    /* in zephyr/dts/arm/st/f4/stm32f4.dtsi:627 */
		status = "disabled";              /* in zephyr/dts/arm/st/f4/stm32f4.dtsi:629 */
		io-channels = < &adc1 0x12 >;     /* in zephyr/dts/arm/st/f4/stm32f411.dtsi:65 */
	};

	/* node '/vref' defined in zephyr/dts/arm/st/f4/stm32f4.dtsi:632 */
	vref: vref {
		compatible = "st,stm32-vref";      /* in zephyr/dts/arm/st/f4/stm32f4.dtsi:633 */
		vrefint-cal-addr = < 0x1fff7a2a >; /* in zephyr/dts/arm/st/f4/stm32f4.dtsi:634 */
		vrefint-cal-mv = < 0xce4 >;        /* in zephyr/dts/arm/st/f4/stm32f4.dtsi:635 */
		io-channels = < &adc1 0x11 >;      /* in zephyr/dts/arm/st/f4/stm32f4.dtsi:636 */
		status = "okay";                   /* in zephyr/boards/weact/blackpill_f411ce/blackpill_f411ce.dts:164 */
	};

	/* node '/vbat' defined in zephyr/dts/arm/st/f4/stm32f4.dtsi:640 */
	vbat: vbat {
		compatible = "st,stm32-vbat"; /* in zephyr/dts/arm/st/f4/stm32f4.dtsi:641 */
		ratio = < 0x4 >;              /* in zephyr/dts/arm/st/f4/stm32f4.dtsi:642 */
		io-channels = < &adc1 0x12 >; /* in zephyr/dts/arm/st/f4/stm32f4.dtsi:643 */
		status = "okay";              /* in zephyr/boards/weact/blackpill_f411ce/blackpill_f411ce.dts:168 */
	};

	/* node '/otgfs_phy' defined in zephyr/dts/arm/st/f4/stm32f4.dtsi:647 */
	otgfs_phy: otgfs_phy {
		compatible = "usb-nop-xceiv"; /* in zephyr/dts/arm/st/f4/stm32f4.dtsi:648 */
		#phy-cells = < 0x0 >;         /* in zephyr/dts/arm/st/f4/stm32f4.dtsi:649 */
		phandle = < 0xd >;            /* in zephyr/dts/arm/st/f4/stm32f4.dtsi:322 */
	};

	/* node '/smbus1' defined in zephyr/dts/arm/st/f4/stm32f4.dtsi:652 */
	smbus1: smbus1 {
		compatible = "st,stm32-smbus"; /* in zephyr/dts/arm/st/f4/stm32f4.dtsi:653 */
		#address-cells = < 0x1 >;      /* in zephyr/dts/arm/st/f4/stm32f4.dtsi:654 */
		#size-cells = < 0x0 >;         /* in zephyr/dts/arm/st/f4/stm32f4.dtsi:655 */
		i2c = < &i2c1 >;               /* in zephyr/dts/arm/st/f4/stm32f4.dtsi:656 */
		status = "disabled";           /* in zephyr/dts/arm/st/f4/stm32f4.dtsi:657 */
	};

	/* node '/smbus2' defined in zephyr/dts/arm/st/f4/stm32f4.dtsi:660 */
	smbus2: smbus2 {
		compatible = "st,stm32-smbus"; /* in zephyr/dts/arm/st/f4/stm32f4.dtsi:661 */
		#address-cells = < 0x1 >;      /* in zephyr/dts/arm/st/f4/stm32f4.dtsi:662 */
		#size-cells = < 0x0 >;         /* in zephyr/dts/arm/st/f4/stm32f4.dtsi:663 */
		i2c = < &i2c2 >;               /* in zephyr/dts/arm/st/f4/stm32f4.dtsi:664 */
		status = "disabled";           /* in zephyr/dts/arm/st/f4/stm32f4.dtsi:665 */
	};

	/* node '/smbus3' defined in zephyr/dts/arm/st/f4/stm32f4.dtsi:668 */
	smbus3: smbus3 {
		compatible = "st,stm32-smbus"; /* in zephyr/dts/arm/st/f4/stm32f4.dtsi:669 */
		#address-cells = < 0x1 >;      /* in zephyr/dts/arm/st/f4/stm32f4.dtsi:670 */
		#size-cells = < 0x0 >;         /* in zephyr/dts/arm/st/f4/stm32f4.dtsi:671 */
		i2c = < &i2c3 >;               /* in zephyr/dts/arm/st/f4/stm32f4.dtsi:672 */
		status = "disabled";           /* in zephyr/dts/arm/st/f4/stm32f4.dtsi:673 */
	};

	/* node '/leds' defined in zephyr/boards/weact/blackpill_f411ce/blackpill_f411ce.dts:24 */
	leds {
		compatible = "gpio-leds"; /* in haptic/app.overlay:9 */

		/* node '/leds/led' defined in zephyr/boards/weact/blackpill_f411ce/blackpill_f411ce.dts:27 */
		user_led: led {
			gpios = < &gpioc 0xd 0x1 >; /* in zephyr/boards/weact/blackpill_f411ce/blackpill_f411ce.dts:28 */
			label = "User LED";         /* in zephyr/boards/weact/blackpill_f411ce/blackpill_f411ce.dts:29 */
		};

		/* node '/leds/led_0' defined in haptic/app.overlay:10 */
		blue_led: led_0 {
			gpios = < &gpioc 0xd 0x1 >; /* in haptic/app.overlay:11 */
		};
	};

	/* node '/gpio_keys' defined in zephyr/boards/weact/blackpill_f411ce/blackpill_f411ce.dts:33 */
	gpio_keys {
		compatible = "gpio-keys"; /* in zephyr/boards/weact/blackpill_f411ce/blackpill_f411ce.dts:34 */

		/* node '/gpio_keys/button' defined in zephyr/boards/weact/blackpill_f411ce/blackpill_f411ce.dts:36 */
		user_button: button {
			label = "KEY";               /* in zephyr/boards/weact/blackpill_f411ce/blackpill_f411ce.dts:37 */
			gpios = < &gpioa 0x0 0x11 >; /* in zephyr/boards/weact/blackpill_f411ce/blackpill_f411ce.dts:38 */
			zephyr,code = < 0xb >;       /* in zephyr/boards/weact/blackpill_f411ce/blackpill_f411ce.dts:39 */
		};
	};
};
